[part 1 of 2: package /STELLANTIS/EPT/COMSWCs]
AUTOSAR XML (schema 4-2-2)
package /STELLANTIS/EPT/COMSWCs
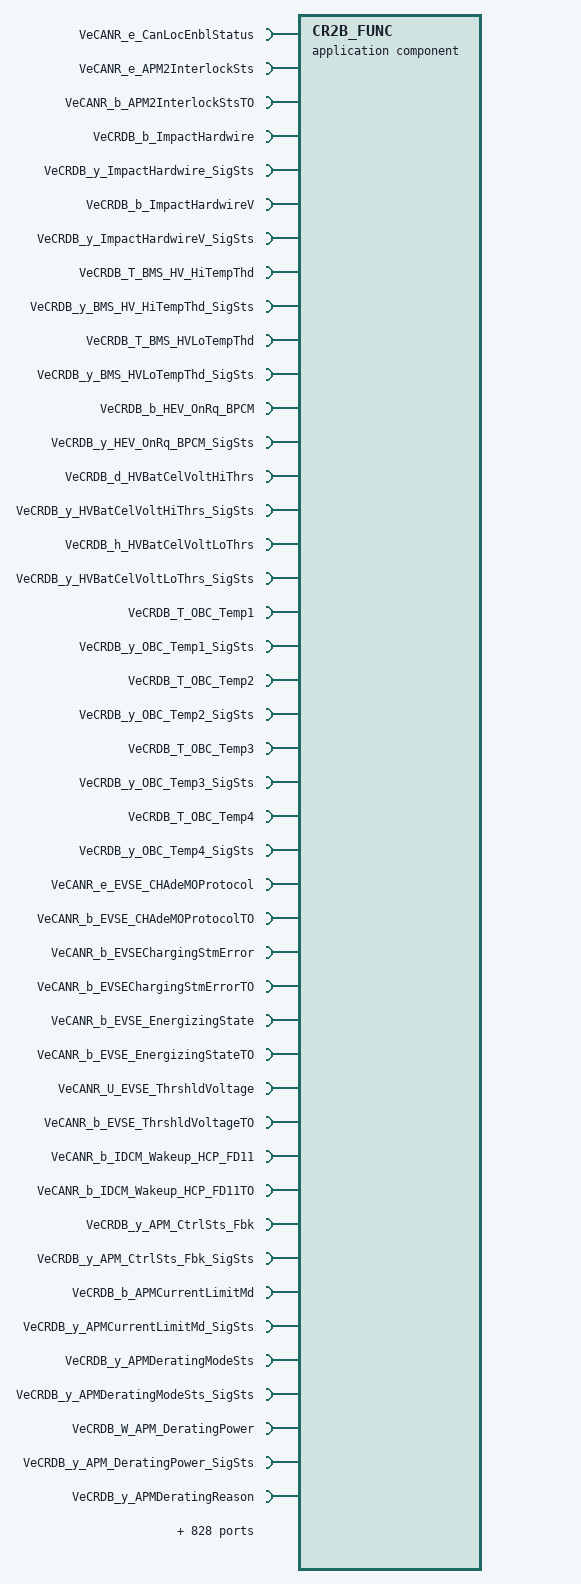
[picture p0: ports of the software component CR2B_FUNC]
  application sw component type CR2B_FUNC
    872 x require port:
      VeCANR_e_CanLocEnblStatus: nonqueued-receiver-com-spec{data-element=VeCANR_e_CanLocEnblStatus, init-value=0}, required-interface=VeCANR_e_CanLocEnblStatus
      VeCANR_e_APM2InterlockSts: nonqueued-receiver-com-spec{data-element=VeCANR_e_APM2InterlockSts, handle-never-received=true, init-value=0}, required-interface=VeCANR_e_APM2InterlockSts
      VeCANR_b_APM2InterlockStsTO: nonqueued-receiver-com-spec{data-element=VeCANR_b_APM2InterlockStsTO, init-value=0}, required-interface=VeCANR_b_APM2InterlockStsTO
      VeCRDB_b_ImpactHardwire: nonqueued-receiver-com-spec{data-element=Value, handle-never-received=true, init-value=0}, required-interface=VeCRDB_b_ImpactHardwire
      VeCRDB_y_ImpactHardwire_SigSts: nonqueued-receiver-com-spec{data-element=Value, init-value=0}, required-interface=VeCRDB_y_ImpactHardwire_SigSts
      VeCRDB_b_ImpactHardwireV: nonqueued-receiver-com-spec{data-element=Value, handle-never-received=true, init-value=0}, required-interface=VeCRDB_b_ImpactHardwireV
      VeCRDB_y_ImpactHardwireV_SigSts: nonqueued-receiver-com-spec{data-element=Value, init-value=0}, required-interface=VeCRDB_y_ImpactHardwireV_SigSts
      VeCRDB_T_BMS_HV_HiTempThd: nonqueued-receiver-com-spec{data-element=Value, handle-never-received=true, init-value=0}, required-interface=VeCRDB_T_BMS_HV_HiTempThd
      VeCRDB_y_BMS_HV_HiTempThd_SigSts: nonqueued-receiver-com-spec{data-element=Value, init-value=0}, required-interface=VeCRDB_y_BMS_HV_HiTempThd_SigSts
      VeCRDB_T_BMS_HVLoTempThd: nonqueued-receiver-com-spec{data-element=Value, handle-never-received=true, init-value=0}, required-interface=VeCRDB_T_BMS_HVLoTempThd
      VeCRDB_y_BMS_HVLoTempThd_SigSts: nonqueued-receiver-com-spec{data-element=Value, init-value=0}, required-interface=VeCRDB_y_BMS_HVLoTempThd_SigSts
      VeCRDB_b_HEV_OnRq_BPCM: nonqueued-receiver-com-spec{data-element=Value, handle-never-received=true, init-value=0}, required-interface=VeCRDB_b_HEV_OnRq_BPCM
      VeCRDB_y_HEV_OnRq_BPCM_SigSts: nonqueued-receiver-com-spec{data-element=Value, init-value=0}, required-interface=VeCRDB_y_HEV_OnRq_BPCM_SigSts
      VeCRDB_d_HVBatCelVoltHiThrs: nonqueued-receiver-com-spec{data-element=Value, handle-never-received=true, init-value=0}, required-interface=VeCRDB_d_HVBatCelVoltHiThrs
      VeCRDB_y_HVBatCelVoltHiThrs_SigSts: nonqueued-receiver-com-spec{data-element=Value, init-value=0}, required-interface=VeCRDB_y_HVBatCelVoltHiThrs_SigSts
      VeCRDB_h_HVBatCelVoltLoThrs: nonqueued-receiver-com-spec{data-element=Value, handle-never-received=true, init-value=0}, required-interface=VeCRDB_h_HVBatCelVoltLoThrs
      VeCRDB_y_HVBatCelVoltLoThrs_SigSts: nonqueued-receiver-com-spec{data-element=Value, init-value=0}, required-interface=VeCRDB_y_HVBatCelVoltLoThrs_SigSts
      VeCRDB_T_OBC_Temp1: nonqueued-receiver-com-spec{data-element=Value, handle-never-received=true, init-value=0}, required-interface=VeCRDB_T_OBC_Temp1
      VeCRDB_y_OBC_Temp1_SigSts: nonqueued-receiver-com-spec{data-element=Value, init-value=0}, required-interface=VeCRDB_y_OBC_Temp1_SigSts
      VeCRDB_T_OBC_Temp2: nonqueued-receiver-com-spec{data-element=Value, handle-never-received=true, init-value=0}, required-interface=VeCRDB_T_OBC_Temp2
      VeCRDB_y_OBC_Temp2_SigSts: nonqueued-receiver-com-spec{data-element=Value, init-value=0}, required-interface=VeCRDB_y_OBC_Temp2_SigSts
      VeCRDB_T_OBC_Temp3: nonqueued-receiver-com-spec{data-element=Value, handle-never-received=true, init-value=0}, required-interface=VeCRDB_T_OBC_Temp3
      VeCRDB_y_OBC_Temp3_SigSts: nonqueued-receiver-com-spec{data-element=Value, init-value=0}, required-interface=VeCRDB_y_OBC_Temp3_SigSts
      VeCRDB_T_OBC_Temp4: nonqueued-receiver-com-spec{data-element=Value, handle-never-received=true, init-value=0}, required-interface=VeCRDB_T_OBC_Temp4
      VeCRDB_y_OBC_Temp4_SigSts: nonqueued-receiver-com-spec{data-element=Value, init-value=0}, required-interface=VeCRDB_y_OBC_Temp4_SigSts
      VeCANR_e_EVSE_CHAdeMOProtocol: nonqueued-receiver-com-spec{data-element=VeCANR_e_EVSE_CHAdeMOProtocol, handle-never-received=true, init-value=0}, required-interface=VeCANR_e_EVSE_CHAdeMOProtocol
      VeCANR_b_EVSE_CHAdeMOProtocolTO: nonqueued-receiver-com-spec{data-element=VeCANR_b_EVSE_CHAdeMOProtocolTO, init-value=0}, required-interface=VeCANR_b_EVSE_CHAdeMOProtocolTO
      VeCANR_b_EVSEChargingStmError: nonqueued-receiver-com-spec{data-element=VeCANR_b_EVSEChargingStmError, handle-never-received=true, init-value=0}, required-interface=VeCANR_b_EVSEChargingStmError
      VeCANR_b_EVSEChargingStmErrorTO: nonqueued-receiver-com-spec{data-element=VeCANR_b_EVSEChargingStmErrorTO, init-value=0}, required-interface=VeCANR_b_EVSEChargingStmErrorTO
      VeCANR_b_EVSE_EnergizingState: nonqueued-receiver-com-spec{data-element=VeCANR_b_EVSE_EnergizingState, handle-never-received=true, init-value=0}, required-interface=VeCANR_b_EVSE_EnergizingState
      VeCANR_b_EVSE_EnergizingStateTO: nonqueued-receiver-com-spec{data-element=VeCANR_b_EVSE_EnergizingStateTO, init-value=0}, required-interface=VeCANR_b_EVSE_EnergizingStateTO
      VeCANR_U_EVSE_ThrshldVoltage: nonqueued-receiver-com-spec{data-element=VeCANR_U_EVSE_ThrshldVoltage, handle-never-received=true, init-value=0}, required-interface=VeCANR_U_EVSE_ThrshldVoltage
      VeCANR_b_EVSE_ThrshldVoltageTO: nonqueued-receiver-com-spec{data-element=VeCANR_b_EVSE_ThrshldVoltageTO, init-value=0}, required-interface=VeCANR_b_EVSE_ThrshldVoltageTO
      VeCANR_b_IDCM_Wakeup_HCP_FD11: nonqueued-receiver-com-spec{data-element=VeCANR_b_IDCM_Wakeup_HCP_FD11, handle-never-received=true, init-value=0}, required-interface=VeCANR_b_IDCM_Wakeup_HCP_FD11
      VeCANR_b_IDCM_Wakeup_HCP_FD11TO: nonqueued-receiver-com-spec{data-element=VeCANR_b_IDCM_Wakeup_HCP_FD11TO, init-value=0}, required-interface=VeCANR_b_IDCM_Wakeup_HCP_FD11TO
      VeCRDB_y_APM_CtrlSts_Fbk: nonqueued-receiver-com-spec{data-element=Value, handle-never-received=true, init-value=0}, required-interface=VeCRDB_y_APM_CtrlSts_Fbk
      VeCRDB_y_APM_CtrlSts_Fbk_SigSts: nonqueued-receiver-com-spec{data-element=Value, init-value=0}, required-interface=VeCRDB_y_APM_CtrlSts_Fbk_SigSts
      VeCRDB_b_APMCurrentLimitMd: nonqueued-receiver-com-spec{data-element=Value, handle-never-received=true, init-value=0}, required-interface=VeCRDB_b_APMCurrentLimitMd
      VeCRDB_y_APMCurrentLimitMd_SigSts: nonqueued-receiver-com-spec{data-element=Value, init-value=0}, required-interface=VeCRDB_y_APMCurrentLimitMd_SigSts
      VeCRDB_y_APMDeratingModeSts: nonqueued-receiver-com-spec{data-element=Value, handle-never-received=true, init-value=0}, required-interface=VeCRDB_y_APMDeratingModeSts
      VeCRDB_y_APMDeratingModeSts_SigSts: nonqueued-receiver-com-spec{data-element=Value, init-value=0}, required-interface=VeCRDB_y_APMDeratingModeSts_SigSts
      VeCRDB_W_APM_DeratingPower: nonqueued-receiver-com-spec{data-element=Value, handle-never-received=true, init-value=0}, required-interface=VeCRDB_W_APM_DeratingPower
      VeCRDB_y_APM_DeratingPower_SigSts: nonqueued-receiver-com-spec{data-element=Value, init-value=0}, required-interface=VeCRDB_y_APM_DeratingPower_SigSts
      VeCRDB_y_APMDeratingReason: nonqueued-receiver-com-spec{data-element=Value, handle-never-received=true, init-value=0}, required-interface=VeCRDB_y_APMDeratingReason
      VeCRDB_y_APMDeratingReason_SigSts: nonqueued-receiver-com-spec{data-element=Value, init-value=0}, required-interface=VeCRDB_y_APMDeratingReason_SigSts
      VeCRDB_W_APM_EstPwrLoss: nonqueued-receiver-com-spec{data-element=Value, handle-never-received=true, init-value=0}, required-interface=VeCRDB_W_APM_EstPwrLoss
      VeCRDB_y_APM_EstPwrLoss_SigSts: nonqueued-receiver-com-spec{data-element=Value, init-value=0}, required-interface=VeCRDB_y_APM_EstPwrLoss_SigSts
      VeCRDB_y_APM_FailureReason: nonqueued-receiver-com-spec{data-element=Value, handle-never-received=true, init-value=0}, required-interface=VeCRDB_y_APM_FailureReason
      VeCRDB_y_APM_FailureReason_SigSts: nonqueued-receiver-com-spec{data-element=Value, init-value=0}, required-interface=VeCRDB_y_APM_FailureReason_SigSts
      VeCRDB_y_APM_FailureType: nonqueued-receiver-com-spec{data-element=Value, handle-never-received=true, init-value=0}, required-interface=VeCRDB_y_APM_FailureType
      VeCRDB_y_APM_FailureType_SigSts: nonqueued-receiver-com-spec{data-element=Value, init-value=0}, required-interface=VeCRDB_y_APM_FailureType_SigSts
      VeCRDB_I_APM_HV_I_Fbk: nonqueued-receiver-com-spec{data-element=Value, handle-never-received=true, init-value=0}, required-interface=VeCRDB_I_APM_HV_I_Fbk
      VeCRDB_y_APM_HV_I_Fbk_SigSts: nonqueued-receiver-com-spec{data-element=Value, init-value=0}, required-interface=VeCRDB_y_APM_HV_I_Fbk_SigSts
      VeCRDB_U_APM_HV_V_Fbk: nonqueued-receiver-com-spec{data-element=Value, handle-never-received=true, init-value=0}, required-interface=VeCRDB_U_APM_HV_V_Fbk
      VeCRDB_y_APM_HV_V_Fbk_SigSts: nonqueued-receiver-com-spec{data-element=Value, init-value=0}, required-interface=VeCRDB_y_APM_HV_V_Fbk_SigSts
      VeCRDB_b_APM_HvOverVStatus: nonqueued-receiver-com-spec{data-element=Value, handle-never-received=true, init-value=0}, required-interface=VeCRDB_b_APM_HvOverVStatus
      VeCRDB_y_APM_HvOverVStatus_SigSts: nonqueued-receiver-com-spec{data-element=Value, init-value=0}, required-interface=VeCRDB_y_APM_HvOverVStatus_SigSts
      VeCRDB_U_APM_HvVsetPFdbk: nonqueued-receiver-com-spec{data-element=Value, handle-never-received=true, init-value=0}, required-interface=VeCRDB_U_APM_HvVsetPFdbk
      VeCRDB_y_APM_HvVsetPFdbk_SigSts: nonqueued-receiver-com-spec{data-element=Value, init-value=0}, required-interface=VeCRDB_y_APM_HvVsetPFdbk_SigSts
      VeCRDB_I_APM_IdcHvSetPFdbk: nonqueued-receiver-com-spec{data-element=Value, handle-never-received=true, init-value=0}, required-interface=VeCRDB_I_APM_IdcHvSetPFdbk
      VeCRDB_y_APM_IdcHvSetPFdbk_SigSts: nonqueued-receiver-com-spec{data-element=Value, init-value=0}, required-interface=VeCRDB_y_APM_IdcHvSetPFdbk_SigSts
      VeCRDB_W_APM_InputPower: nonqueued-receiver-com-spec{data-element=Value, handle-never-received=true, init-value=0}, required-interface=VeCRDB_W_APM_InputPower
      VeCRDB_y_APM_InputPower_SigSts: nonqueued-receiver-com-spec{data-element=Value, init-value=0}, required-interface=VeCRDB_y_APM_InputPower_SigSts
      VeCRDB_I_APM_LV_I_Fbk: nonqueued-receiver-com-spec{data-element=Value, handle-never-received=true, init-value=0}, required-interface=VeCRDB_I_APM_LV_I_Fbk
      VeCRDB_y_APM_LV_I_Fbk_SigSts: nonqueued-receiver-com-spec{data-element=Value, init-value=0}, required-interface=VeCRDB_y_APM_LV_I_Fbk_SigSts
      VeCRDB_U_APM_LV_V_Fbk: nonqueued-receiver-com-spec{data-element=Value, handle-never-received=true, init-value=0}, required-interface=VeCRDB_U_APM_LV_V_Fbk
      VeCRDB_y_APM_LV_V_Fbk_SigSts: nonqueued-receiver-com-spec{data-element=Value, init-value=0}, required-interface=VeCRDB_y_APM_LV_V_Fbk_SigSts
      VeCRDB_W_APM_OutputPower: nonqueued-receiver-com-spec{data-element=Value, handle-never-received=true, init-value=0}, required-interface=VeCRDB_W_APM_OutputPower
      VeCRDB_y_APM_OutputPower_SigSts: nonqueued-receiver-com-spec{data-element=Value, init-value=0}, required-interface=VeCRDB_y_APM_OutputPower_SigSts
      VeCRDB_T_APM_PSFB_Temp1: nonqueued-receiver-com-spec{data-element=Value, handle-never-received=true, init-value=0}, required-interface=VeCRDB_T_APM_PSFB_Temp1
      VeCRDB_y_APM_PSFB_Temp1_SigSts: nonqueued-receiver-com-spec{data-element=Value, init-value=0}, required-interface=VeCRDB_y_APM_PSFB_Temp1_SigSts
      VeCRDB_T_APM_PSFB_Temp2: nonqueued-receiver-com-spec{data-element=Value, handle-never-received=true, init-value=0}, required-interface=VeCRDB_T_APM_PSFB_Temp2
      VeCRDB_y_APM_PSFB_Temp2_SigSts: nonqueued-receiver-com-spec{data-element=Value, init-value=0}, required-interface=VeCRDB_y_APM_PSFB_Temp2_SigSts
      VeCRDB_b_APM_PowerLimitMode: nonqueued-receiver-com-spec{data-element=Value, handle-never-received=true, init-value=0}, required-interface=VeCRDB_b_APM_PowerLimitMode
      VeCRDB_y_APM_PowerLimitMode_SigSts: nonqueued-receiver-com-spec{data-element=Value, init-value=0}, required-interface=VeCRDB_y_APM_PowerLimitMode_SigSts
      VeCRDB_T_APM_TempColdPlate: nonqueued-receiver-com-spec{data-element=Value, handle-never-received=true, init-value=0}, required-interface=VeCRDB_T_APM_TempColdPlate
      VeCRDB_y_APM_TempColdPlate_SigSts: nonqueued-receiver-com-spec{data-element=Value, init-value=0}, required-interface=VeCRDB_y_APM_TempColdPlate_SigSts
      VeCRDB_y_APM_ThermalRunaway: nonqueued-receiver-com-spec{data-element=Value, handle-never-received=true, init-value=0}, required-interface=VeCRDB_y_APM_ThermalRunaway
      VeCRDB_y_APM_ThermalRunaway_SigSts: nonqueued-receiver-com-spec{data-element=Value, init-value=0}, required-interface=VeCRDB_y_APM_ThermalRunaway_SigSts
      VeCRDB_Pct_APMUtlPctOfDCDC: nonqueued-receiver-com-spec{data-element=Value, handle-never-received=true, init-value=0}, required-interface=VeCRDB_Pct_APMUtlPctOfDCDC
      VeCRDB_y_APMUtlPctOfDCDC_SigSts: nonqueued-receiver-com-spec{data-element=Value, init-value=0}, required-interface=VeCRDB_y_APMUtlPctOfDCDC_SigSts
      VeCRDB_b_BPCMCntctrsMTOWrn: nonqueued-receiver-com-spec{data-element=Value, handle-never-received=true, init-value=0}, required-interface=VeCRDB_b_BPCMCntctrsMTOWrn
      VeCRDB_y_BPCMCntctrsMTOWrn_SigSts: nonqueued-receiver-com-spec{data-element=Value, init-value=0}, required-interface=VeCRDB_y_BPCMCntctrsMTOWrn_SigSts
      VeCRDB_b_BPCMCntctrsSTOWrn: nonqueued-receiver-com-spec{data-element=Value, handle-never-received=true, init-value=0}, required-interface=VeCRDB_b_BPCMCntctrsSTOWrn
      VeCRDB_y_BPCMCntctrsSTOWrn_SigSts: nonqueued-receiver-com-spec{data-element=Value, init-value=0}, required-interface=VeCRDB_y_BPCMCntctrsSTOWrn_SigSts
      VeCRDB_dT_BPCM_HVCelMxDchImp: nonqueued-receiver-com-spec{data-element=Value, handle-never-received=true, init-value=0}, required-interface=VeCRDB_dT_BPCM_HVCelMxDchImp
      VeCRDB_y_BPCM_HVCelMxDchImp_SigSts: nonqueued-receiver-com-spec{data-element=Value, init-value=0}, required-interface=VeCRDB_y_BPCM_HVCelMxDchImp_SigSts
      VeCRDB_dT_BPCM_HVClMinDchImp: nonqueued-receiver-com-spec{data-element=Value, handle-never-received=true, init-value=0}, required-interface=VeCRDB_dT_BPCM_HVClMinDchImp
      VeCRDB_y_BPCM_HVClMinDchImp_SigSts: nonqueued-receiver-com-spec{data-element=Value, init-value=0}, required-interface=VeCRDB_y_BPCM_HVClMinDchImp_SigSts
      VeCRDB_I_BPCM_HVChrgCurProf: nonqueued-receiver-com-spec{data-element=Value, handle-never-received=true, init-value=0}, required-interface=VeCRDB_I_BPCM_HVChrgCurProf
      VeCRDB_y_BPCM_HVChrgCurProf_SigSts: nonqueued-receiver-com-spec{data-element=Value, init-value=0}, required-interface=VeCRDB_y_BPCM_HVChrgCurProf_SigSts
      VeCRDB_y_BPCM_HV_BatChrgSts: nonqueued-receiver-com-spec{data-element=Value, handle-never-received=true, init-value=0}, required-interface=VeCRDB_y_BPCM_HV_BatChrgSts
      VeCRDB_y_BPCM_HV_BatChrgSts_SigSts: nonqueued-receiver-com-spec{data-element=Value, init-value=0}, required-interface=VeCRDB_y_BPCM_HV_BatChrgSts_SigSts
      VeCRDB_P_BPCM_HVPwrMaxChgLT: nonqueued-receiver-com-spec{data-element=Value, handle-never-received=true, init-value=0}, required-interface=VeCRDB_P_BPCM_HVPwrMaxChgLT
      VeCRDB_y_BPCM_HVPwrMaxChgLT_SigSts: nonqueued-receiver-com-spec{data-element=Value, init-value=0}, required-interface=VeCRDB_y_BPCM_HVPwrMaxChgLT_SigSts
      VeCRDB_P_BPCM_HVPwrMaxChgMT: nonqueued-receiver-com-spec{data-element=Value, handle-never-received=true, init-value=0}, required-interface=VeCRDB_P_BPCM_HVPwrMaxChgMT
      VeCRDB_y_BPCM_HVPwrMaxChgMT_SigSts: nonqueued-receiver-com-spec{data-element=Value, init-value=0}, required-interface=VeCRDB_y_BPCM_HVPwrMaxChgMT_SigSts
      VeCRDB_P_BPCM_HVPwrMaxChgST: nonqueued-receiver-com-spec{data-element=Value, handle-never-received=true, init-value=0}, required-interface=VeCRDB_P_BPCM_HVPwrMaxChgST
      VeCRDB_y_BPCM_HVPwrMaxChgST_SigSts: nonqueued-receiver-com-spec{data-element=Value, init-value=0}, required-interface=VeCRDB_y_BPCM_HVPwrMaxChgST_SigSts
      VeCRDB_P_BPCM_HVPwrMxDchgLT: nonqueued-receiver-com-spec{data-element=Value, handle-never-received=true, init-value=0}, required-interface=VeCRDB_P_BPCM_HVPwrMxDchgLT
      VeCRDB_y_BPCM_HVPwrMxDchgLT_SigSts: nonqueued-receiver-com-spec{data-element=Value, init-value=0}, required-interface=VeCRDB_y_BPCM_HVPwrMxDchgLT_SigSts
      VeCRDB_P_BPCM_HVPwrMxDchgMT: nonqueued-receiver-com-spec{data-element=Value, handle-never-received=true, init-value=0}, required-interface=VeCRDB_P_BPCM_HVPwrMxDchgMT
      VeCRDB_y_BPCM_HVPwrMxDchgMT_SigSts: nonqueued-receiver-com-spec{data-element=Value, init-value=0}, required-interface=VeCRDB_y_BPCM_HVPwrMxDchgMT_SigSts
      VeCRDB_P_BPCM_HVPwrMxDchgST: nonqueued-receiver-com-spec{data-element=Value, handle-never-received=true, init-value=0}, required-interface=VeCRDB_P_BPCM_HVPwrMxDchgST
      VeCRDB_y_BPCM_HVPwrMxDchgST_SigSts: nonqueued-receiver-com-spec{data-element=Value, init-value=0}, required-interface=VeCRDB_y_BPCM_HVPwrMxDchgST_SigSts
      VeCRDB_y_BPCMInterlockSts: nonqueued-receiver-com-spec{data-element=Value, handle-never-received=true, init-value=0}, required-interface=VeCRDB_y_BPCMInterlockSts
      VeCRDB_y_BPCMInterlockSts_SigSts: nonqueued-receiver-com-spec{data-element=Value, init-value=0}, required-interface=VeCRDB_y_BPCMInterlockSts_SigSts
      VeCRDB_b_BPCM_DCCntctrMTOW: nonqueued-receiver-com-spec{data-element=Value, handle-never-received=true, init-value=0}, required-interface=VeCRDB_b_BPCM_DCCntctrMTOW
      VeCRDB_y_BPCM_DCCntctrMTOW_SigSts: nonqueued-receiver-com-spec{data-element=Value, init-value=0}, required-interface=VeCRDB_y_BPCM_DCCntctrMTOW_SigSts
      VeCRDB_b_BPCM_DCCntctrSTOW: nonqueued-receiver-com-spec{data-element=Value, handle-never-received=true, init-value=0}, required-interface=VeCRDB_b_BPCM_DCCntctrSTOW
      VeCRDB_y_BPCM_DCCntctrSTOW_SigSts: nonqueued-receiver-com-spec{data-element=Value, init-value=0}, required-interface=VeCRDB_y_BPCM_DCCntctrSTOW_SigSts
      VeCRDB_y_BPCM_HV_BalngMd: nonqueued-receiver-com-spec{data-element=Value, handle-never-received=true, init-value=0}, required-interface=VeCRDB_y_BPCM_HV_BalngMd
      VeCRDB_y_BPCM_HV_BalngMd_SigSts: nonqueued-receiver-com-spec{data-element=Value, init-value=0}, required-interface=VeCRDB_y_BPCM_HV_BalngMd_SigSts
      VeCRDB_y_BPCM_HVBIIS: nonqueued-receiver-com-spec{data-element=Value, handle-never-received=true, init-value=0}, required-interface=VeCRDB_y_BPCM_HVBIIS
      VeCRDB_y_BPCM_HVBIIS_SigSts: nonqueued-receiver-com-spec{data-element=Value, init-value=0}, required-interface=VeCRDB_y_BPCM_HVBIIS_SigSts
      VeCRDB_y_BPCM_HVBattGFDSts: nonqueued-receiver-com-spec{data-element=Value, handle-never-received=true, init-value=0}, required-interface=VeCRDB_y_BPCM_HVBattGFDSts
      VeCRDB_y_BPCM_HVBattGFDSts_SigSts: nonqueued-receiver-com-spec{data-element=Value, init-value=0}, required-interface=VeCRDB_y_BPCM_HVBattGFDSts_SigSts
      VeCRDB_qAhr_BPCM_HV_Capacity: nonqueued-receiver-com-spec{data-element=Value, handle-never-received=true, init-value=0}, required-interface=VeCRDB_qAhr_BPCM_HV_Capacity
      VeCRDB_y_BPCM_HV_Capacity_SigSts: nonqueued-receiver-com-spec{data-element=Value, init-value=0}, required-interface=VeCRDB_y_BPCM_HV_Capacity_SigSts
      VeCRDB_y_BPCM_HVChrgBusSts: nonqueued-receiver-com-spec{data-element=Value, handle-never-received=true, init-value=0}, required-interface=VeCRDB_y_BPCM_HVChrgBusSts
      VeCRDB_y_BPCM_HVChrgBusSts_SigSts: nonqueued-receiver-com-spec{data-element=Value, init-value=0}, required-interface=VeCRDB_y_BPCM_HVChrgBusSts_SigSts
      VeCRDB_I_BPCM_HV_Current: nonqueued-receiver-com-spec{data-element=Value, handle-never-received=true, init-value=0}, required-interface=VeCRDB_I_BPCM_HV_Current
      VeCRDB_y_BPCM_HV_Current_SigSts: nonqueued-receiver-com-spec{data-element=Value, init-value=0}, required-interface=VeCRDB_y_BPCM_HV_Current_SigSts
      VeCRDB_I_BPCM_HV_CurrentString2: nonqueued-receiver-com-spec{data-element=Value, handle-never-received=true, init-value=0}, required-interface=VeCRDB_I_BPCM_HV_CurrentString2
      VeCRDB_y_BPCM_HV_CurrentString2_SigSts: nonqueued-receiver-com-spec{data-element=Value, init-value=0}, required-interface=VeCRDB_y_BPCM_HV_CurrentString2_SigSts
      VeCRDB_y_BPCM_HV_DCFC_IsolatnSts: nonqueued-receiver-com-spec{data-element=Value, handle-never-received=true, init-value=0}, required-interface=VeCRDB_y_BPCM_HV_DCFC_IsolatnSts
      VeCRDB_y_BPCM_HV_DCFC_IsolatnSts_SigSts: nonqueued-receiver-com-spec{data-element=Value, init-value=0}, required-interface=VeCRDB_y_BPCM_HV_DCFC_IsolatnSts_SigSts
      VeCRDB_T_BPCM_HV_Inlet_Temp: nonqueued-receiver-com-spec{data-element=Value, handle-never-received=true, init-value=0}, required-interface=VeCRDB_T_BPCM_HV_Inlet_Temp
      VeCRDB_y_BPCM_HV_Inlet_Temp_SigSts: nonqueued-receiver-com-spec{data-element=Value, init-value=0}, required-interface=VeCRDB_y_BPCM_HV_Inlet_Temp_SigSts
      VeCRDB_U_BPCM_HV_IntVolt: nonqueued-receiver-com-spec{data-element=Value, handle-never-received=true, init-value=0}, required-interface=VeCRDB_U_BPCM_HV_IntVolt
      VeCRDB_y_BPCM_HV_IntVolt_SigSts: nonqueued-receiver-com-spec{data-element=Value, init-value=0}, required-interface=VeCRDB_y_BPCM_HV_IntVolt_SigSts
      VeCRDB_U_BPCM_HVIntrnlVltStrng1: nonqueued-receiver-com-spec{data-element=Value, handle-never-received=true, init-value=0}, required-interface=VeCRDB_U_BPCM_HVIntrnlVltStrng1
      VeCRDB_y_BPCM_HVIntrnlVltStrng1_SigSts: nonqueued-receiver-com-spec{data-element=Value, init-value=0}, required-interface=VeCRDB_y_BPCM_HVIntrnlVltStrng1_SigSts
      VeCRDB_U_BPCM_HVIntrnlVltStrng2: nonqueued-receiver-com-spec{data-element=Value, handle-never-received=true, init-value=0}, required-interface=VeCRDB_U_BPCM_HVIntrnlVltStrng2
      VeCRDB_y_BPCM_HVIntrnlVltStrng2_SigSts: nonqueued-receiver-com-spec{data-element=Value, init-value=0}, required-interface=VeCRDB_y_BPCM_HVIntrnlVltStrng2_SigSts
      VeCRDB_T_BPCM_HV_Outl_Temp: nonqueued-receiver-com-spec{data-element=Value, handle-never-received=true, init-value=0}, required-interface=VeCRDB_T_BPCM_HV_Outl_Temp
      VeCRDB_y_BPCM_HV_Outl_Temp_SigSts: nonqueued-receiver-com-spec{data-element=Value, init-value=0}, required-interface=VeCRDB_y_BPCM_HV_Outl_Temp_SigSts
      VeCRDB_Pct_BPCM_HV_SOC: nonqueued-receiver-com-spec{data-element=Value, handle-never-received=true, init-value=0}, required-interface=VeCRDB_Pct_BPCM_HV_SOC
      VeCRDB_y_BPCM_HV_SOC_SigSts: nonqueued-receiver-com-spec{data-element=Value, init-value=0}, required-interface=VeCRDB_y_BPCM_HV_SOC_SigSts
      VeCRDB_y_BPCM_HV_SOH: nonqueued-receiver-com-spec{data-element=Value, handle-never-received=true, init-value=0}, required-interface=VeCRDB_y_BPCM_HV_SOH
      VeCRDB_y_BPCM_HV_SOH_SigSts: nonqueued-receiver-com-spec{data-element=Value, init-value=0}, required-interface=VeCRDB_y_BPCM_HV_SOH_SigSts
      VeCRDB_y_BPCM_HV_SOH_Low: nonqueued-receiver-com-spec{data-element=Value, handle-never-received=true, init-value=0}, required-interface=VeCRDB_y_BPCM_HV_SOH_Low
      VeCRDB_y_BPCM_HV_SOH_Low_SigSts: nonqueued-receiver-com-spec{data-element=Value, init-value=0}, required-interface=VeCRDB_y_BPCM_HV_SOH_Low_SigSts
      VeCRDB_T_BPCM_HV_Temp_Avg: nonqueued-receiver-com-spec{data-element=Value, handle-never-received=true, init-value=0}, required-interface=VeCRDB_T_BPCM_HV_Temp_Avg
      VeCRDB_y_BPCM_HV_Temp_Avg_SigSts: nonqueued-receiver-com-spec{data-element=Value, init-value=0}, required-interface=VeCRDB_y_BPCM_HV_Temp_Avg_SigSts
      VeCRDB_T_BPCM_HV_Temp_Max: nonqueued-receiver-com-spec{data-element=Value, handle-never-received=true, init-value=0}, required-interface=VeCRDB_T_BPCM_HV_Temp_Max
      VeCRDB_y_BPCM_HV_Temp_Max_SigSts: nonqueued-receiver-com-spec{data-element=Value, init-value=0}, required-interface=VeCRDB_y_BPCM_HV_Temp_Max_SigSts
      VeCRDB_T_BPCM_HV_Temp_Min: nonqueued-receiver-com-spec{data-element=Value, handle-never-received=true, init-value=0}, required-interface=VeCRDB_T_BPCM_HV_Temp_Min
      VeCRDB_y_BPCM_HV_Temp_Min_SigSts: nonqueued-receiver-com-spec{data-element=Value, init-value=0}, required-interface=VeCRDB_y_BPCM_HV_Temp_Min_SigSts
      VeCRDB_y_BPCM_HV_ThermRnway: nonqueued-receiver-com-spec{data-element=Value, handle-never-received=true, init-value=0}, required-interface=VeCRDB_y_BPCM_HV_ThermRnway
      VeCRDB_y_BPCM_HV_ThermRnway_SigSts: nonqueued-receiver-com-spec{data-element=Value, init-value=0}, required-interface=VeCRDB_y_BPCM_HV_ThermRnway_SigSts
      VeCRDB_y_BPCM_HV_TracBusSts: nonqueued-receiver-com-spec{data-element=Value, handle-never-received=true, init-value=0}, required-interface=VeCRDB_y_BPCM_HV_TracBusSts
      VeCRDB_y_BPCM_HV_TracBusSts_SigSts: nonqueued-receiver-com-spec{data-element=Value, init-value=0}, required-interface=VeCRDB_y_BPCM_HV_TracBusSts_SigSts
      VeCRDB_y_BPCM_HVTracMainCntacCfg: variation-point={short-label=vpVeCRDB_y_BPCM_HVTracMainCntacCfg, sw-syscond=1}, nonqueued-receiver-com-spec{data-element=Value, handle-never-received=true, init-value=0}, required-interface=VeCRDB_y_BPCM_HVTracMainCntacCfg
      VeCRDB_y_BPCM_HVTracMainCntacCfg_SigSts: variation-point={short-label=vpVeCRDB_y_BPCM_HVTracMainCntacCfg_SigSts, sw-syscond=1}, nonqueued-receiver-com-spec{data-element=Value, init-value=0}, required-interface=VeCRDB_y_BPCM_HVTracMainCntacCfg_SigSts
      VeCRDB_y_BPCM_HVTracMCS: nonqueued-receiver-com-spec{data-element=Value, handle-never-received=true, init-value=0}, required-interface=VeCRDB_y_BPCM_HVTracMCS
      VeCRDB_y_BPCM_HVTracMCS_SigSts: nonqueued-receiver-com-spec{data-element=Value, init-value=0}, required-interface=VeCRDB_y_BPCM_HVTracMCS_SigSts
      VeCRDB_U_BPCM_HVTracBusVolt: nonqueued-receiver-com-spec{data-element=Value, handle-never-received=true, init-value=0}, required-interface=VeCRDB_U_BPCM_HVTracBusVolt
      VeCRDB_y_BPCM_HVTracBusVolt_SigSts: nonqueued-receiver-com-spec{data-element=Value, init-value=0}, required-interface=VeCRDB_y_BPCM_HVTracBusVolt_SigSts
      VeCRDB_b_BPCM_PwrLimpHm: nonqueued-receiver-com-spec{data-element=Value, handle-never-received=true, init-value=0}, required-interface=VeCRDB_b_BPCM_PwrLimpHm
      VeCRDB_y_BPCM_PwrLimpHm_SigSts: nonqueued-receiver-com-spec{data-element=Value, init-value=0}, required-interface=VeCRDB_y_BPCM_PwrLimpHm_SigSts
      VeCRDB_b_BPCM_ReqforAuxLoadoff: variation-point={short-label=vpVeCRDB_b_BPCM_ReqforAuxLoadoff, sw-syscond=1}, nonqueued-receiver-com-spec{data-element=Value, handle-never-received=true, init-value=0}, required-interface=VeCRDB_b_BPCM_ReqforAuxLoadoff
      VeCRDB_y_BPCM_ReqforAuxLoadoff_SigSts: variation-point={short-label=vpVeCRDB_y_BPCM_ReqforAuxLoadoff_SigSts, sw-syscond=1}, nonqueued-receiver-com-spec{data-element=Value, init-value=0}, required-interface=VeCRDB_y_BPCM_ReqforAuxLoadoff_SigSts
      VeCRDB_U_BPCM_Series_Voltage: variation-point={short-label=vpVeCRDB_U_BPCM_Series_Voltage, sw-syscond=1}, nonqueued-receiver-com-spec{data-element=Value, handle-never-received=true, init-value=0}, required-interface=VeCRDB_U_BPCM_Series_Voltage
      VeCRDB_y_BPCM_Series_Voltage_SigSts: variation-point={short-label=vpVeCRDB_y_BPCM_Series_Voltage_SigSts, sw-syscond=1}, nonqueued-receiver-com-spec{data-element=Value, init-value=0}, required-interface=VeCRDB_y_BPCM_Series_Voltage_SigSts
      VeCRDB_y_DC_Charge_Type_Status: variation-point={short-label=vpVeCRDB_y_DC_Charge_Type_Status, sw-syscond=1}, nonqueued-receiver-com-spec{data-element=Value, handle-never-received=true, init-value=0}, required-interface=VeCRDB_y_DC_Charge_Type_Status
      VeCRDB_y_DC_Charge_Type_Status_SigSts: variation-point={short-label=vpVeCRDB_y_DC_Charge_Type_Status_SigSts, sw-syscond=1}, nonqueued-receiver-com-spec{data-element=Value, init-value=0}, required-interface=VeCRDB_y_DC_Charge_Type_Status_SigSts
      VeCRDB_T_HVBP_BDU_Busbar_Temp: nonqueued-receiver-com-spec{data-element=Value, handle-never-received=true, init-value=0}, required-interface=VeCRDB_T_HVBP_BDU_Busbar_Temp
      VeCRDB_y_HVBP_BDU_Busbar_Temp_SigSts: nonqueued-receiver-com-spec{data-element=Value, init-value=0}, required-interface=VeCRDB_y_HVBP_BDU_Busbar_Temp_SigSts
      VeCRDB_T_HVBP_Busbar_Temp: nonqueued-receiver-com-spec{data-element=Value, handle-never-received=true, init-value=0}, required-interface=VeCRDB_T_HVBP_Busbar_Temp
      VeCRDB_y_HVBP_Busbar_Temp_SigSts: nonqueued-receiver-com-spec{data-element=Value, init-value=0}, required-interface=VeCRDB_y_HVBP_Busbar_Temp_SigSts
      VeCRDB_thr_HVBatCntctOpnTime: nonqueued-receiver-com-spec{data-element=Value, handle-never-received=true, init-value=0}, required-interface=VeCRDB_thr_HVBatCntctOpnTime
      VeCRDB_y_HVBatCntctOpnTime_SigSts: nonqueued-receiver-com-spec{data-element=Value, init-value=0}, required-interface=VeCRDB_y_HVBatCntctOpnTime_SigSts
      VeCRDB_b_HVBatCntctWeldChk: nonqueued-receiver-com-spec{data-element=Value, handle-never-received=true, init-value=0}, required-interface=VeCRDB_b_HVBatCntctWeldChk
      VeCRDB_y_HVBatCntctWeldChk_SigSts: nonqueued-receiver-com-spec{data-element=Value, init-value=0}, required-interface=VeCRDB_y_HVBatCntctWeldChk_SigSts
      VeCRDB_tdy_HVBatLastSlept: nonqueued-receiver-com-spec{data-element=Value, handle-never-received=true, init-value=0}, required-interface=VeCRDB_tdy_HVBatLastSlept
      VeCRDB_y_HVBatLastSlept_SigSts: nonqueued-receiver-com-spec{data-element=Value, init-value=0}, required-interface=VeCRDB_y_HVBatLastSlept_SigSts
      VeCRDB_b_HVBatReady: nonqueued-receiver-com-spec{data-element=Value, handle-never-received=true, init-value=0}, required-interface=VeCRDB_b_HVBatReady
      VeCRDB_y_HVBatReady_SigSts: nonqueued-receiver-com-spec{data-element=Value, init-value=0}, required-interface=VeCRDB_y_HVBatReady_SigSts
      VeCRDB_U_BPCM_Cell_VoltAvg: nonqueued-receiver-com-spec{data-element=Value, handle-never-received=true, init-value=0}, required-interface=VeCRDB_U_BPCM_Cell_VoltAvg
      VeCRDB_y_BPCM_Cell_VoltAvg_SigSts: nonqueued-receiver-com-spec{data-element=Value, init-value=0}, required-interface=VeCRDB_y_BPCM_Cell_VoltAvg_SigSts
      VeCRDB_U_BPCM_Cell_Volt_Max: nonqueued-receiver-com-spec{data-element=Value, handle-never-received=true, init-value=0}, required-interface=VeCRDB_U_BPCM_Cell_Volt_Max
      VeCRDB_y_BPCM_Cell_Volt_Max_SigSts: nonqueued-receiver-com-spec{data-element=Value, init-value=0}, required-interface=VeCRDB_y_BPCM_Cell_Volt_Max_SigSts
      VeCRDB_U_BPCM_Cell_Volt_Min: nonqueued-receiver-com-spec{data-element=Value, handle-never-received=true, init-value=0}, required-interface=VeCRDB_U_BPCM_Cell_Volt_Min
      VeCRDB_y_BPCM_Cell_Volt_Min_SigSts: nonqueued-receiver-com-spec{data-element=Value, init-value=0}, required-interface=VeCRDB_y_BPCM_Cell_Volt_Min_SigSts
      VeCRDB_d_BPCM_HVNrCelMaxTmp: nonqueued-receiver-com-spec{data-element=Value, handle-never-received=true, init-value=0}, required-interface=VeCRDB_d_BPCM_HVNrCelMaxTmp
      VeCRDB_y_BPCM_HVNrCelMaxTmp_SigSts: nonqueued-receiver-com-spec{data-element=Value, init-value=0}, required-interface=VeCRDB_y_BPCM_HVNrCelMaxTmp_SigSts
      VeCRDB_d_BPCM_HVNrCelMaxVlt: nonqueued-receiver-com-spec{data-element=Value, handle-never-received=true, init-value=0}, required-interface=VeCRDB_d_BPCM_HVNrCelMaxVlt
      VeCRDB_y_BPCM_HVNrCelMaxVlt_SigSts: nonqueued-receiver-com-spec{data-element=Value, init-value=0}, required-interface=VeCRDB_y_BPCM_HVNrCelMaxVlt_SigSts
      VeCRDB_d_BPCM_HVNrCelMinTmp: nonqueued-receiver-com-spec{data-element=Value, handle-never-received=true, init-value=0}, required-interface=VeCRDB_d_BPCM_HVNrCelMinTmp
      VeCRDB_y_BPCM_HVNrCelMinTmp_SigSts: nonqueued-receiver-com-spec{data-element=Value, init-value=0}, required-interface=VeCRDB_y_BPCM_HVNrCelMinTmp_SigSts
      VeCRDB_d_BPCM_HVNrCelMinVlt: nonqueued-receiver-com-spec{data-element=Value, handle-never-received=true, init-value=0}, required-interface=VeCRDB_d_BPCM_HVNrCelMinVlt
      VeCRDB_y_BPCM_HVNrCelMinVlt_SigSts: nonqueued-receiver-com-spec{data-element=Value, init-value=0}, required-interface=VeCRDB_y_BPCM_HVNrCelMinVlt_SigSts
      VeCRDB_U_BPCMMaxCelVoltAlwd: nonqueued-receiver-com-spec{data-element=Value, handle-never-received=true, init-value=0}, required-interface=VeCRDB_U_BPCMMaxCelVoltAlwd
      VeCRDB_y_BPCMMaxCelVoltAlwd_SigSts: nonqueued-receiver-com-spec{data-element=Value, init-value=0}, required-interface=VeCRDB_y_BPCMMaxCelVoltAlwd_SigSts
      VeCRDB_U_BPCMMaxPkVoltAllwd: nonqueued-receiver-com-spec{data-element=Value, handle-never-received=true, init-value=0}, required-interface=VeCRDB_U_BPCMMaxPkVoltAllwd
      VeCRDB_y_BPCMMaxPkVoltAllwd_SigSts: nonqueued-receiver-com-spec{data-element=Value, init-value=0}, required-interface=VeCRDB_y_BPCMMaxPkVoltAllwd_SigSts
      VeCRDB_U_BPCMMinCelVoltAlwd: nonqueued-receiver-com-spec{data-element=Value, handle-never-received=true, init-value=0}, required-interface=VeCRDB_U_BPCMMinCelVoltAlwd
      VeCRDB_y_BPCMMinCelVoltAlwd_SigSts: nonqueued-receiver-com-spec{data-element=Value, init-value=0}, required-interface=VeCRDB_y_BPCMMinCelVoltAlwd_SigSts
      VeCRDB_U_BPCMMinPkVoltAllwd: nonqueued-receiver-com-spec{data-element=Value, handle-never-received=true, init-value=0}, required-interface=VeCRDB_U_BPCMMinPkVoltAllwd
      VeCRDB_y_BPCMMinPkVoltAllwd_SigSts: nonqueued-receiver-com-spec{data-element=Value, init-value=0}, required-interface=VeCRDB_y_BPCMMinPkVoltAllwd_SigSts
      VeCRDB_U_BPCM_OCVAvgCelVolt: nonqueued-receiver-com-spec{data-element=Value, handle-never-received=true, init-value=0}, required-interface=VeCRDB_U_BPCM_OCVAvgCelVolt
      VeCRDB_y_BPCM_OCVAvgCelVolt_SigSts: nonqueued-receiver-com-spec{data-element=Value, init-value=0}, required-interface=VeCRDB_y_BPCM_OCVAvgCelVolt_SigSts
      VeCRDB_U_BPCM_OCVMaxCelVolt: nonqueued-receiver-com-spec{data-element=Value, handle-never-received=true, init-value=0}, required-interface=VeCRDB_U_BPCM_OCVMaxCelVolt
      VeCRDB_y_BPCM_OCVMaxCelVolt_SigSts: nonqueued-receiver-com-spec{data-element=Value, init-value=0}, required-interface=VeCRDB_y_BPCM_OCVMaxCelVolt_SigSts
      VeCRDB_U_BPCM_OCVMinCelVolt: nonqueued-receiver-com-spec{data-element=Value, handle-never-received=true, init-value=0}, required-interface=VeCRDB_U_BPCM_OCVMinCelVolt
      VeCRDB_y_BPCM_OCVMinCelVolt_SigSts: nonqueued-receiver-com-spec{data-element=Value, init-value=0}, required-interface=VeCRDB_y_BPCM_OCVMinCelVolt_SigSts
      VeCRDB_b_AC_LnHi: nonqueued-receiver-com-spec{data-element=Value, handle-never-received=true, init-value=0}, required-interface=VeCRDB_b_AC_LnHi
      VeCRDB_y_AC_LnHi_SigSts: nonqueued-receiver-com-spec{data-element=Value, init-value=0}, required-interface=VeCRDB_y_AC_LnHi_SigSts
      VeCRDB_b_AC_LnLow: nonqueued-receiver-com-spec{data-element=Value, handle-never-received=true, init-value=0}, required-interface=VeCRDB_b_AC_LnLow
      VeCRDB_y_AC_LnLow_SigSts: nonqueued-receiver-com-spec{data-element=Value, init-value=0}, required-interface=VeCRDB_y_AC_LnLow_SigSts
      VeCRDB_b_AC_Present: nonqueued-receiver-com-spec{data-element=Value, handle-never-received=true, init-value=0}, required-interface=VeCRDB_b_AC_Present
      VeCRDB_y_AC_Present_SigSts: nonqueued-receiver-com-spec{data-element=Value, init-value=0}, required-interface=VeCRDB_y_AC_Present_SigSts
      VeCRDB_I_AC_Side_Curr1: nonqueued-receiver-com-spec{data-element=Value, handle-never-received=true, init-value=0}, required-interface=VeCRDB_I_AC_Side_Curr1
      VeCRDB_y_AC_Side_Curr1_SigSts: nonqueued-receiver-com-spec{data-element=Value, init-value=0}, required-interface=VeCRDB_y_AC_Side_Curr1_SigSts
      VeCRDB_I_AC_Side_Curr2: nonqueued-receiver-com-spec{data-element=Value, handle-never-received=true, init-value=0}, required-interface=VeCRDB_I_AC_Side_Curr2
      VeCRDB_y_AC_Side_Curr2_SigSts: nonqueued-receiver-com-spec{data-element=Value, init-value=0}, required-interface=VeCRDB_y_AC_Side_Curr2_SigSts
      VeCRDB_I_AC_Side_Curr3: nonqueued-receiver-com-spec{data-element=Value, handle-never-received=true, init-value=0}, required-interface=VeCRDB_I_AC_Side_Curr3
      VeCRDB_y_AC_Side_Curr3_SigSts: nonqueued-receiver-com-spec{data-element=Value, init-value=0}, required-interface=VeCRDB_y_AC_Side_Curr3_SigSts
      VeCRDB_U_AC_Side_Volt1: nonqueued-receiver-com-spec{data-element=Value, handle-never-received=true, init-value=0}, required-interface=VeCRDB_U_AC_Side_Volt1
      VeCRDB_y_AC_Side_Volt1_SigSts: nonqueued-receiver-com-spec{data-element=Value, init-value=0}, required-interface=VeCRDB_y_AC_Side_Volt1_SigSts
      VeCRDB_U_AC_Side_Volt2: nonqueued-receiver-com-spec{data-element=Value, handle-never-received=true, init-value=0}, required-interface=VeCRDB_U_AC_Side_Volt2
      VeCRDB_y_AC_Side_Volt2_SigSts: nonqueued-receiver-com-spec{data-element=Value, init-value=0}, required-interface=VeCRDB_y_AC_Side_Volt2_SigSts
      VeCRDB_U_AC_Side_Volt3: nonqueued-receiver-com-spec{data-element=Value, handle-never-received=true, init-value=0}, required-interface=VeCRDB_U_AC_Side_Volt3
      VeCRDB_y_AC_Side_Volt3_SigSts: nonqueued-receiver-com-spec{data-element=Value, init-value=0}, required-interface=VeCRDB_y_AC_Side_Volt3_SigSts
      VeCRDB_I_BatterySideCurrent: nonqueued-receiver-com-spec{data-element=Value, handle-never-received=true, init-value=0}, required-interface=VeCRDB_I_BatterySideCurrent
      VeCRDB_y_BatterySideCurrent_SigSts: nonqueued-receiver-com-spec{data-element=Value, init-value=0}, required-interface=VeCRDB_y_BatterySideCurrent_SigSts
      VeCRDB_U_BatterySideVoltage: nonqueued-receiver-com-spec{data-element=Value, handle-never-received=true, init-value=0}, required-interface=VeCRDB_U_BatterySideVoltage
      VeCRDB_y_BatterySideVoltage_SigSts: nonqueued-receiver-com-spec{data-element=Value, init-value=0}, required-interface=VeCRDB_y_BatterySideVoltage_SigSts
      VeCRDB_I_ChargeCurrent: nonqueued-receiver-com-spec{data-element=Value, handle-never-received=true, init-value=0}, required-interface=VeCRDB_I_ChargeCurrent
      VeCRDB_y_ChargeCurrent_SigSts: nonqueued-receiver-com-spec{data-element=Value, init-value=0}, required-interface=VeCRDB_y_ChargeCurrent_SigSts
      VeCRDB_I_ChrgCurrAvail: nonqueued-receiver-com-spec{data-element=Value, handle-never-received=true, init-value=0}, required-interface=VeCRDB_I_ChrgCurrAvail
      VeCRDB_y_ChrgCurrAvail_SigSts: nonqueued-receiver-com-spec{data-element=Value, init-value=0}, required-interface=VeCRDB_y_ChrgCurrAvail_SigSts
      VeCRDB_y_ControlPilotSts: nonqueued-receiver-com-spec{data-element=Value, handle-never-received=true, init-value=0}, required-interface=VeCRDB_y_ControlPilotSts
      VeCRDB_y_ControlPilotSts_SigSts: nonqueued-receiver-com-spec{data-element=Value, init-value=0}, required-interface=VeCRDB_y_ControlPilotSts_SigSts
      VeCRDB_y_EVCCFailrReason: nonqueued-receiver-com-spec{data-element=Value, handle-never-received=true, init-value=0}, required-interface=VeCRDB_y_EVCCFailrReason
      VeCRDB_y_EVCCFailrReason_SigSts: nonqueued-receiver-com-spec{data-element=Value, init-value=0}, required-interface=VeCRDB_y_EVCCFailrReason_SigSts
      VeCRDB_I_InputCurrentAvail: nonqueued-receiver-com-spec{data-element=Value, handle-never-received=true, init-value=0}, required-interface=VeCRDB_I_InputCurrentAvail
      VeCRDB_y_InputCurrentAvail_SigSts: nonqueued-receiver-com-spec{data-element=Value, init-value=0}, required-interface=VeCRDB_y_InputCurrentAvail_SigSts
      VeCRDB_b_J1772_S2_Sts: nonqueued-receiver-com-spec{data-element=Value, handle-never-received=true, init-value=0}, required-interface=VeCRDB_b_J1772_S2_Sts
      VeCRDB_y_J1772_S2_Sts_SigSts: nonqueued-receiver-com-spec{data-element=Value, init-value=0}, required-interface=VeCRDB_y_J1772_S2_Sts_SigSts
      VeCRDB_y_J1772_State: nonqueued-receiver-com-spec{data-element=Value, handle-never-received=true, init-value=0}, required-interface=VeCRDB_y_J1772_State
      VeCRDB_y_J1772_State_SigSts: nonqueued-receiver-com-spec{data-element=Value, init-value=0}, required-interface=VeCRDB_y_J1772_State_SigSts
      VeCRDB_y_OBCInterlockSts: nonqueued-receiver-com-spec{data-element=Value, handle-never-received=true, init-value=0}, required-interface=VeCRDB_y_OBCInterlockSts
      VeCRDB_y_OBCInterlockSts_SigSts: nonqueued-receiver-com-spec{data-element=Value, init-value=0}, required-interface=VeCRDB_y_OBCInterlockSts_SigSts
      VeCRDB_y_OBCM_SdpSts: nonqueued-receiver-com-spec{data-element=Value, handle-never-received=true, init-value=0}, required-interface=VeCRDB_y_OBCM_SdpSts
      VeCRDB_y_OBCM_SdpSts_SigSts: nonqueued-receiver-com-spec{data-element=Value, init-value=0}, required-interface=VeCRDB_y_OBCM_SdpSts_SigSts
      VeCRDB_y_OBCM_SlacSts: nonqueued-receiver-com-spec{data-element=Value, handle-never-received=true, init-value=0}, required-interface=VeCRDB_y_OBCM_SlacSts
      VeCRDB_y_OBCM_SlacSts_SigSts: nonqueued-receiver-com-spec{data-element=Value, init-value=0}, required-interface=VeCRDB_y_OBCM_SlacSts_SigSts
      VeCRDB_y_ProximitySts: nonqueued-receiver-com-spec{data-element=Value, handle-never-received=true, init-value=0}, required-interface=VeCRDB_y_ProximitySts
      VeCRDB_y_ProximitySts_SigSts: nonqueued-receiver-com-spec{data-element=Value, init-value=0}, required-interface=VeCRDB_y_ProximitySts_SigSts
      VeCRDB_y_SuprtdProtocolName: nonqueued-receiver-com-spec{data-element=Value, handle-never-received=true, init-value=0}, required-interface=VeCRDB_y_SuprtdProtocolName
      VeCRDB_y_SuprtdProtocolName_SigSts: nonqueued-receiver-com-spec{data-element=Value, init-value=0}, required-interface=VeCRDB_y_SuprtdProtocolName_SigSts
      VeCRDB_y_Supported_SchemaID: nonqueued-receiver-com-spec{data-element=Value, handle-never-received=true, init-value=0}, required-interface=VeCRDB_y_Supported_SchemaID
      VeCRDB_y_Supported_SchemaID_SigSts: nonqueued-receiver-com-spec{data-element=Value, init-value=0}, required-interface=VeCRDB_y_Supported_SchemaID_SigSts
      VeCRDB_y_SuprtdVerNrMajor: nonqueued-receiver-com-spec{data-element=Value, handle-never-received=true, init-value=0}, required-interface=VeCRDB_y_SuprtdVerNrMajor
      VeCRDB_y_SuprtdVerNrMajor_SigSts: nonqueued-receiver-com-spec{data-element=Value, init-value=0}, required-interface=VeCRDB_y_SuprtdVerNrMajor_SigSts
      VeCRDB_y_SuprtdVerNrMinor: nonqueued-receiver-com-spec{data-element=Value, handle-never-received=true, init-value=0}, required-interface=VeCRDB_y_SuprtdVerNrMinor
      VeCRDB_y_SuprtdVerNrMinor_SigSts: nonqueued-receiver-com-spec{data-element=Value, init-value=0}, required-interface=VeCRDB_y_SuprtdVerNrMinor_SigSts
      VeCRDB_y_ChrgFailSts: nonqueued-receiver-com-spec{data-element=Value, handle-never-received=true, init-value=0}, required-interface=VeCRDB_y_ChrgFailSts
      VeCRDB_y_ChrgFailSts_SigSts: nonqueued-receiver-com-spec{data-element=Value, init-value=0}, required-interface=VeCRDB_y_ChrgFailSts_SigSts
      VeCRDB_U_OBC_Prox: nonqueued-receiver-com-spec{data-element=Value, handle-never-received=true, init-value=0}, required-interface=VeCRDB_U_OBC_Prox
      VeCRDB_y_OBC_Prox_SigSts: nonqueued-receiver-com-spec{data-element=Value, init-value=0}, required-interface=VeCRDB_y_OBC_Prox_SigSts
      VeCRDB_y_OnboardChargerMode: nonqueued-receiver-com-spec{data-element=Value, handle-never-received=true, init-value=0}, required-interface=VeCRDB_y_OnboardChargerMode
      VeCRDB_y_OnboardChargerMode_SigSts: nonqueued-receiver-com-spec{data-element=Value, init-value=0}, required-interface=VeCRDB_y_OnboardChargerMode_SigSts
      VeCRDB_y_OnboardChrgrReady: nonqueued-receiver-com-spec{data-element=Value, handle-never-received=true, init-value=0}, required-interface=VeCRDB_y_OnboardChrgrReady
      VeCRDB_y_OnboardChrgrReady_SigSts: nonqueued-receiver-com-spec{data-element=Value, init-value=0}, required-interface=VeCRDB_y_OnboardChrgrReady_SigSts
      VeCRDB_b_EVSE_OfdACSingPhas: nonqueued-receiver-com-spec{data-element=Value, handle-never-received=true, init-value=0}, required-interface=VeCRDB_b_EVSE_OfdACSingPhas
      VeCRDB_y_EVSE_OfdACSingPhas_SigSts: nonqueued-receiver-com-spec{data-element=Value, init-value=0}, required-interface=VeCRDB_y_EVSE_OfdACSingPhas_SigSts
      VeCRDB_b_EVSEOfdACThreePhas: nonqueued-receiver-com-spec{data-element=Value, handle-never-received=true, init-value=0}, required-interface=VeCRDB_b_EVSEOfdACThreePhas
      VeCRDB_y_EVSEOfdACThreePhas_SigSts: nonqueued-receiver-com-spec{data-element=Value, init-value=0}, required-interface=VeCRDB_y_EVSEOfdACThreePhas_SigSts
      VeSR1B_b_EVSE_Ofd_DC_Extended: nonqueued-receiver-com-spec{data-element=Value, handle-never-received=true, init-value=0}, required-interface=VeSR1B_b_EVSE_Ofd_DC_Extended
      VeSR1B_y_EVSE_Ofd_DC_Extended_SigSts: nonqueued-receiver-com-spec{data-element=Value, init-value=0}, required-interface=VeSR1B_y_EVSE_Ofd_DC_Extended_SigSts
      VeSR1B_b_EVSEServ1ChargnFD11: nonqueued-receiver-com-spec{data-element=Value, handle-never-received=true, init-value=0}, required-interface=VeSR1B_b_EVSEServ1ChargnFD11
      VeSR1B_y_EVSEServ1ChargnFD11_SigSts: nonqueued-receiver-com-spec{data-element=Value, init-value=0}, required-interface=VeSR1B_y_EVSEServ1ChargnFD11_SigSts
      VeSR1B_b_EVSE_Service1_FreeFD11: nonqueued-receiver-com-spec{data-element=Value, handle-never-received=true, init-value=0}, required-interface=VeSR1B_b_EVSE_Service1_FreeFD11
      VeSR1B_y_EVSE_Service1_FreeFD11_SigSts: nonqueued-receiver-com-spec{data-element=Value, init-value=0}, required-interface=VeSR1B_y_EVSE_Service1_FreeFD11_SigSts
      VeSR1B_cmp_ISO15118EVSETiStFD11: nonqueued-receiver-com-spec{data-element=Value, handle-never-received=true, init-value=0}, required-interface=VeSR1B_cmp_ISO15118EVSETiStFD11
      VeSR1B_y_ISO15118EVSETiStFD11_SigSts: nonqueued-receiver-com-spec{data-element=Value, init-value=0}, required-interface=VeSR1B_y_ISO15118EVSETiStFD11_SigSts
      VeSR1B_y_ISO15118_MsgRespFD11: nonqueued-receiver-com-spec{data-element=Value, handle-never-received=true, init-value=0}, required-interface=VeSR1B_y_ISO15118_MsgRespFD11
      VeSR1B_y_ISO15118_MsgRespFD11_SigSts: nonqueued-receiver-com-spec{data-element=Value, init-value=0}, required-interface=VeSR1B_y_ISO15118_MsgRespFD11_SigSts
      VeSR1B_t_ISO15118NtfcnMxDlyFD11: nonqueued-receiver-com-spec{data-element=Value, handle-never-received=true, init-value=0}, required-interface=VeSR1B_t_ISO15118NtfcnMxDlyFD11
      VeSR1B_y_ISO15118NtfcnMxDlyFD11_SigSts: nonqueued-receiver-com-spec{data-element=Value, init-value=0}, required-interface=VeSR1B_y_ISO15118NtfcnMxDlyFD11_SigSts
      VeSR1B_y_ISO15118_RespCodFD11: nonqueued-receiver-com-spec{data-element=Value, handle-never-received=true, init-value=0}, required-interface=VeSR1B_y_ISO15118_RespCodFD11
      VeSR1B_y_ISO15118_RespCodFD11_SigSts: nonqueued-receiver-com-spec{data-element=Value, init-value=0}, required-interface=VeSR1B_y_ISO15118_RespCodFD11_SigSts
      VeSR1B_y_ISO15118SAScdlTlIDFD11: nonqueued-receiver-com-spec{data-element=Value, handle-never-received=true, init-value=0}, required-interface=VeSR1B_y_ISO15118SAScdlTlIDFD11
      VeSR1B_y_ISO15118SAScdlTlIDFD11_SigSts: nonqueued-receiver-com-spec{data-element=Value, init-value=0}, required-interface=VeSR1B_y_ISO15118SAScdlTlIDFD11_SigSts
      VeSR1B_y_ISO15118_SchemaID_FD11: nonqueued-receiver-com-spec{data-element=Value, handle-never-received=true, init-value=0}, required-interface=VeSR1B_y_ISO15118_SchemaID_FD11
      VeSR1B_y_ISO15118_SchemaID_FD11_SigSts: nonqueued-receiver-com-spec{data-element=Value, init-value=0}, required-interface=VeSR1B_y_ISO15118_SchemaID_FD11_SigSts
      VeSR1B_d_ISO15118_ServiceIDFD11: nonqueued-receiver-com-spec{data-element=Value, handle-never-received=true, init-value=0}, required-interface=VeSR1B_d_ISO15118_ServiceIDFD11
      VeSR1B_y_ISO15118_ServiceIDFD11_SigSts: nonqueued-receiver-com-spec{data-element=Value, init-value=0}, required-interface=VeSR1B_y_ISO15118_ServiceIDFD11_SigSts
      VeSR1B_b_ISO15118_TLSoffrdFD11: nonqueued-receiver-com-spec{data-element=Value, handle-never-received=true, init-value=0}, required-interface=VeSR1B_b_ISO15118_TLSoffrdFD11
      VeSR1B_y_ISO15118_TLSoffrdFD11_SigSts: nonqueued-receiver-com-spec{data-element=Value, init-value=0}, required-interface=VeSR1B_y_ISO15118_TLSoffrdFD11_SigSts
      VeSR1B_y_ISO15118_TLSStatusFD11: nonqueued-receiver-com-spec{data-element=Value, handle-never-received=true, init-value=0}, required-interface=VeSR1B_y_ISO15118_TLSStatusFD11
      VeSR1B_y_ISO15118_TLSStatusFD11_SigSts: nonqueued-receiver-com-spec{data-element=Value, init-value=0}, required-interface=VeSR1B_y_ISO15118_TLSStatusFD11_SigSts
      VeSR1B_y_ISO15118VrsnNmMajrFD11: nonqueued-receiver-com-spec{data-element=Value, handle-never-received=true, init-value=0}, required-interface=VeSR1B_y_ISO15118VrsnNmMajrFD11
      VeSR1B_y_ISO15118VrsnNmMajrFD11_SigSts: nonqueued-receiver-com-spec{data-element=Value, init-value=0}, required-interface=VeSR1B_y_ISO15118VrsnNmMajrFD11_SigSts
      VeSR1B_y_ISO15118VrsnNmMinrFD11: nonqueued-receiver-com-spec{data-element=Value, handle-never-received=true, init-value=0}, required-interface=VeSR1B_y_ISO15118VrsnNmMinrFD11
      VeSR1B_y_ISO15118VrsnNmMinrFD11_SigSts: nonqueued-receiver-com-spec{data-element=Value, init-value=0}, required-interface=VeSR1B_y_ISO15118VrsnNmMinrFD11_SigSts
      VeSR1B_b_V2X_EVSE_Service5_Free: nonqueued-receiver-com-spec{data-element=Value, handle-never-received=true, init-value=0}, required-interface=VeSR1B_b_V2X_EVSE_Service5_Free
      VeSR1B_y_V2X_EVSE_Service5_Free_SigSts: nonqueued-receiver-com-spec{data-element=Value, init-value=0}, required-interface=VeSR1B_y_V2X_EVSE_Service5_Free_SigSts
      VeCRDB_b_DC_Isoln_Dsbl_Cmd: nonqueued-receiver-com-spec{data-element=Value, handle-never-received=true, init-value=0}, required-interface=VeCRDB_b_DC_Isoln_Dsbl_Cmd
      VeCRDB_y_DC_Isoln_Dsbl_Cmd_SigSts: nonqueued-receiver-com-spec{data-element=Value, init-value=0}, required-interface=VeCRDB_y_DC_Isoln_Dsbl_Cmd_SigSts
      VeCRDB_b_DC_TimeOut: nonqueued-receiver-com-spec{data-element=Value, handle-never-received=true, init-value=0}, required-interface=VeCRDB_b_DC_TimeOut
      VeCRDB_y_DC_TimeOut_SigSts: nonqueued-receiver-com-spec{data-element=Value, init-value=0}, required-interface=VeCRDB_y_DC_TimeOut_SigSts
      VeCRDB_d_EVSE_Acptd_Prtcl: nonqueued-receiver-com-spec{data-element=Value, handle-never-received=true, init-value=0}, required-interface=VeCRDB_d_EVSE_Acptd_Prtcl
      VeCRDB_y_EVSE_Acptd_Prtcl_SigSts: nonqueued-receiver-com-spec{data-element=Value, init-value=0}, required-interface=VeCRDB_y_EVSE_Acptd_Prtcl_SigSts
      VeCRDB_b_EVSE_FreeService: nonqueued-receiver-com-spec{data-element=Value, handle-never-received=true, init-value=0}, required-interface=VeCRDB_b_EVSE_FreeService
      VeCRDB_y_EVSE_FreeService_SigSts: nonqueued-receiver-com-spec{data-element=Value, init-value=0}, required-interface=VeCRDB_y_EVSE_FreeService_SigSts
      VeCRDB_y_EVSE_IsolationSts: nonqueued-receiver-com-spec{data-element=Value, handle-never-received=true, init-value=0}, required-interface=VeCRDB_y_EVSE_IsolationSts
      VeCRDB_y_EVSE_IsolationSts_SigSts: nonqueued-receiver-com-spec{data-element=Value, init-value=0}, required-interface=VeCRDB_y_EVSE_IsolationSts_SigSts
      VeCRDB_y_EVSE_Notification: nonqueued-receiver-com-spec{data-element=Value, handle-never-received=true, init-value=0}, required-interface=VeCRDB_y_EVSE_Notification
      VeCRDB_y_EVSE_Notification_SigSts: nonqueued-receiver-com-spec{data-element=Value, init-value=0}, required-interface=VeCRDB_y_EVSE_Notification_SigSts
      VeCRDB_y_EVSEOfrdEgyTrfTyp: nonqueued-receiver-com-spec{data-element=Value, handle-never-received=true, init-value=0}, required-interface=VeCRDB_y_EVSEOfrdEgyTrfTyp
      VeCRDB_y_EVSEOfrdEgyTrfTyp_SigSts: nonqueued-receiver-com-spec{data-element=Value, init-value=0}, required-interface=VeCRDB_y_EVSEOfrdEgyTrfTyp_SigSts
      VeCRDB_b_EVSE_OfdPymtCntct: nonqueued-receiver-com-spec{data-element=Value, handle-never-received=true, init-value=0}, required-interface=VeCRDB_b_EVSE_OfdPymtCntct
      VeCRDB_y_EVSE_OfdPymtCntct_SigSts: nonqueued-receiver-com-spec{data-element=Value, init-value=0}, required-interface=VeCRDB_y_EVSE_OfdPymtCntct_SigSts
      VeCRDB_b_EVSE_OfrdPymntEIM: nonqueued-receiver-com-spec{data-element=Value, handle-never-received=true, init-value=0}, required-interface=VeCRDB_b_EVSE_OfrdPymntEIM
      VeCRDB_y_EVSE_OfrdPymntEIM_SigSts: nonqueued-receiver-com-spec{data-element=Value, init-value=0}, required-interface=VeCRDB_y_EVSE_OfrdPymntEIM_SigSts
      VeCRDB_y_EVSE_OfrdPmtOptn: nonqueued-receiver-com-spec{data-element=Value, handle-never-received=true, init-value=0}, required-interface=VeCRDB_y_EVSE_OfrdPmtOptn
      VeCRDB_y_EVSE_OfrdPmtOptn_SigSts: nonqueued-receiver-com-spec{data-element=Value, init-value=0}, required-interface=VeCRDB_y_EVSE_OfrdPmtOptn_SigSts
      VeCRDB_y_EVSE_OfrdServ: nonqueued-receiver-com-spec{data-element=Value, handle-never-received=true, init-value=0}, required-interface=VeCRDB_y_EVSE_OfrdServ
      VeCRDB_y_EVSE_OfrdServ_SigSts: nonqueued-receiver-com-spec{data-element=Value, init-value=0}, required-interface=VeCRDB_y_EVSE_OfrdServ_SigSts
      VeCRDB_b_EVSE_Srvc2Crtfct: nonqueued-receiver-com-spec{data-element=Value, handle-never-received=true, init-value=0}, required-interface=VeCRDB_b_EVSE_Srvc2Crtfct
      VeCRDB_y_EVSE_Srvc2Crtfct_SigSts: nonqueued-receiver-com-spec{data-element=Value, init-value=0}, required-interface=VeCRDB_y_EVSE_Srvc2Crtfct_SigSts
      VeCRDB_d_EVSE_ServiceId: nonqueued-receiver-com-spec{data-element=Value, handle-never-received=true, init-value=0}, required-interface=VeCRDB_d_EVSE_ServiceId
      VeCRDB_y_EVSE_ServiceId_SigSts: nonqueued-receiver-com-spec{data-element=Value, init-value=0}, required-interface=VeCRDB_y_EVSE_ServiceId_SigSts
      VeCRDB_b_EVSE_Supportd_DIN: nonqueued-receiver-com-spec{data-element=Value, handle-never-received=true, init-value=0}, required-interface=VeCRDB_b_EVSE_Supportd_DIN
      VeCRDB_y_EVSE_Supportd_DIN_SigSts: nonqueued-receiver-com-spec{data-element=Value, init-value=0}, required-interface=VeCRDB_y_EVSE_Supportd_DIN_SigSts
      VeCRDB_b_EVSE_Supprtd_ISO1: nonqueued-receiver-com-spec{data-element=Value, handle-never-received=true, init-value=0}, required-interface=VeCRDB_b_EVSE_Supprtd_ISO1
      VeCRDB_y_EVSE_Supprtd_ISO1_SigSts: nonqueued-receiver-com-spec{data-element=Value, init-value=0}, required-interface=VeCRDB_y_EVSE_Supprtd_ISO1_SigSts
      VeCRDB_I_HVCMS_EVSECurRglTl: nonqueued-receiver-com-spec{data-element=Value, handle-never-received=true, init-value=0}, required-interface=VeCRDB_I_HVCMS_EVSECurRglTl
      VeCRDB_y_HVCMS_EVSECurRglTl_SigSts: nonqueued-receiver-com-spec{data-element=Value, init-value=0}, required-interface=VeCRDB_y_HVCMS_EVSECurRglTl_SigSts
      VeCRDB_y_HVCMS_EVSECurLmAch: nonqueued-receiver-com-spec{data-element=Value, handle-never-received=true, init-value=0}, required-interface=VeCRDB_y_HVCMS_EVSECurLmAch
      VeCRDB_y_HVCMS_EVSECurLmAch_SigSts: nonqueued-receiver-com-spec{data-element=Value, init-value=0}, required-interface=VeCRDB_y_HVCMS_EVSECurLmAch_SigSts
      VeCRDB_I_HVCMS_EVSEMaxCurLm: nonqueued-receiver-com-spec{data-element=Value, handle-never-received=true, init-value=0}, required-interface=VeCRDB_I_HVCMS_EVSEMaxCurLm
      VeCRDB_y_HVCMS_EVSEMaxCurLm_SigSts: nonqueued-receiver-com-spec{data-element=Value, init-value=0}, required-interface=VeCRDB_y_HVCMS_EVSEMaxCurLm_SigSts
      VeCRDB_W_HVCMS_EVSEMaxPwrLm: nonqueued-receiver-com-spec{data-element=Value, handle-never-received=true, init-value=0}, required-interface=VeCRDB_W_HVCMS_EVSEMaxPwrLm
      VeCRDB_y_HVCMS_EVSEMaxPwrLm_SigSts: nonqueued-receiver-com-spec{data-element=Value, init-value=0}, required-interface=VeCRDB_y_HVCMS_EVSEMaxPwrLm_SigSts
      VeCRDB_U_HVCMS_EVSEMaxVltLm: nonqueued-receiver-com-spec{data-element=Value, handle-never-received=true, init-value=0}, required-interface=VeCRDB_U_HVCMS_EVSEMaxVltLm
      VeCRDB_y_HVCMS_EVSEMaxVltLm_SigSts: nonqueued-receiver-com-spec{data-element=Value, init-value=0}, required-interface=VeCRDB_y_HVCMS_EVSEMaxVltLm_SigSts
      VeCRDB_I_HVCMS_EVSEMinCurLm: nonqueued-receiver-com-spec{data-element=Value, handle-never-received=true, init-value=0}, required-interface=VeCRDB_I_HVCMS_EVSEMinCurLm
      VeCRDB_y_HVCMS_EVSEMinCurLm_SigSts: nonqueued-receiver-com-spec{data-element=Value, init-value=0}, required-interface=VeCRDB_y_HVCMS_EVSEMinCurLm_SigSts
      VeCRDB_U_HVCMS_EVSEMinVltLm: nonqueued-receiver-com-spec{data-element=Value, handle-never-received=true, init-value=0}, required-interface=VeCRDB_U_HVCMS_EVSEMinVltLm
      VeCRDB_y_HVCMS_EVSEMinVltLm_SigSts: nonqueued-receiver-com-spec{data-element=Value, init-value=0}, required-interface=VeCRDB_y_HVCMS_EVSEMinVltLm_SigSts
      VeCRDB_I_HVCMS_EVSEPkCurRpl: nonqueued-receiver-com-spec{data-element=Value, handle-never-received=true, init-value=0}, required-interface=VeCRDB_I_HVCMS_EVSEPkCurRpl
      VeCRDB_y_HVCMS_EVSEPkCurRpl_SigSts: nonqueued-receiver-com-spec{data-element=Value, init-value=0}, required-interface=VeCRDB_y_HVCMS_EVSEPkCurRpl_SigSts
      VeCRDB_y_HVCMS_EVSEPwrLmAch: nonqueued-receiver-com-spec{data-element=Value, handle-never-received=true, init-value=0}, required-interface=VeCRDB_y_HVCMS_EVSEPwrLmAch
      VeCRDB_y_HVCMS_EVSEPwrLmAch_SigSts: nonqueued-receiver-com-spec{data-element=Value, init-value=0}, required-interface=VeCRDB_y_HVCMS_EVSEPwrLmAch_SigSts
      VeCRDB_I_HVCMS_EVSEPrsntCur: nonqueued-receiver-com-spec{data-element=Value, handle-never-received=true, init-value=0}, required-interface=VeCRDB_I_HVCMS_EVSEPrsntCur
      VeCRDB_y_HVCMS_EVSEPrsntCur_SigSts: nonqueued-receiver-com-spec{data-element=Value, init-value=0}, required-interface=VeCRDB_y_HVCMS_EVSEPrsntCur_SigSts
      VeCRDB_U_HVCMS_EVSEPrsntVlt: nonqueued-receiver-com-spec{data-element=Value, handle-never-received=true, init-value=0}, required-interface=VeCRDB_U_HVCMS_EVSEPrsntVlt
      VeCRDB_y_HVCMS_EVSEPrsntVlt_SigSts: nonqueued-receiver-com-spec{data-element=Value, init-value=0}, required-interface=VeCRDB_y_HVCMS_EVSEPrsntVlt_SigSts
      VeCRDB_b_HVCMS_EVSEProcg: nonqueued-receiver-com-spec{data-element=Value, handle-never-received=true, init-value=0}, required-interface=VeCRDB_b_HVCMS_EVSEProcg
      VeCRDB_y_HVCMS_EVSEProcg_SigSts: nonqueued-receiver-com-spec{data-element=Value, init-value=0}, required-interface=VeCRDB_y_HVCMS_EVSEProcg_SigSts
      VeCRDB_y_HVCMS_EVSEStsCod: nonqueued-receiver-com-spec{data-element=Value, handle-never-received=true, init-value=0}, required-interface=VeCRDB_y_HVCMS_EVSEStsCod
      VeCRDB_y_HVCMS_EVSEStsCod_SigSts: nonqueued-receiver-com-spec{data-element=Value, init-value=0}, required-interface=VeCRDB_y_HVCMS_EVSEStsCod_SigSts
      VeCRDB_y_HVCMS_EVSEVltLmAch: nonqueued-receiver-com-spec{data-element=Value, handle-never-received=true, init-value=0}, required-interface=VeCRDB_y_HVCMS_EVSEVltLmAch
      VeCRDB_y_HVCMS_EVSEVltLmAch_SigSts: nonqueued-receiver-com-spec{data-element=Value, init-value=0}, required-interface=VeCRDB_y_HVCMS_EVSEVltLmAch_SigSts
      VeCRDB_EWhr_HVCMS_EgToBDlvd: nonqueued-receiver-com-spec{data-element=Value, handle-never-received=true, init-value=0}, required-interface=VeCRDB_EWhr_HVCMS_EgToBDlvd
      VeCRDB_y_HVCMS_EgToBDlvd_SigSts: nonqueued-receiver-com-spec{data-element=Value, init-value=0}, required-interface=VeCRDB_y_HVCMS_EgToBDlvd_SigSts
      VeCRDB_y_HVCMS_ResponseCode: nonqueued-receiver-com-spec{data-element=Value, handle-never-received=true, init-value=0}, required-interface=VeCRDB_y_HVCMS_ResponseCode
      VeCRDB_y_HVCMS_ResponseCode_SigSts: nonqueued-receiver-com-spec{data-element=Value, init-value=0}, required-interface=VeCRDB_y_HVCMS_ResponseCode_SigSts
      VeCRDB_y_HVCMS_TxMsgStat: nonqueued-receiver-com-spec{data-element=Value, handle-never-received=true, init-value=0}, required-interface=VeCRDB_y_HVCMS_TxMsgStat
      VeCRDB_y_HVCMS_TxMsgStat_SigSts: nonqueued-receiver-com-spec{data-element=Value, init-value=0}, required-interface=VeCRDB_y_HVCMS_TxMsgStat_SigSts
      VeCRDB_y_OBCM_PLCTypeSts: nonqueued-receiver-com-spec{data-element=Value, handle-never-received=true, init-value=0}, required-interface=VeCRDB_y_OBCM_PLCTypeSts
      VeCRDB_y_OBCM_PLCTypeSts_SigSts: nonqueued-receiver-com-spec{data-element=Value, init-value=0}, required-interface=VeCRDB_y_OBCM_PLCTypeSts_SigSts
      VeCRDB_b_ReceiptRequired: nonqueued-receiver-com-spec{data-element=Value, handle-never-received=true, init-value=0}, required-interface=VeCRDB_b_ReceiptRequired
      VeCRDB_y_ReceiptRequired_SigSts: nonqueued-receiver-com-spec{data-element=Value, init-value=0}, required-interface=VeCRDB_y_ReceiptRequired_SigSts
      VeSR1B_b_V2X_EVSE_Service_5_V2H: nonqueued-receiver-com-spec{data-element=Value, handle-never-received=true, init-value=0}, required-interface=VeSR1B_b_V2X_EVSE_Service_5_V2H
      VeSR1B_y_V2X_EVSE_Service_5_V2H_SigSts: nonqueued-receiver-com-spec{data-element=Value, init-value=0}, required-interface=VeSR1B_y_V2X_EVSE_Service_5_V2H_SigSts
      VeCRDB_y_ChargerFaultStates: nonqueued-receiver-com-spec{data-element=Value, handle-never-received=true, init-value=0}, required-interface=VeCRDB_y_ChargerFaultStates
      VeCRDB_y_ChargerFaultStates_SigSts: nonqueued-receiver-com-spec{data-element=Value, init-value=0}, required-interface=VeCRDB_y_ChargerFaultStates_SigSts
      VeCRDB_y_ChrgrWldDtctAvail: nonqueued-receiver-com-spec{data-element=Value, handle-never-received=true, init-value=0}, required-interface=VeCRDB_y_ChrgrWldDtctAvail
      VeCRDB_y_ChrgrWldDtctAvail_SigSts: nonqueued-receiver-com-spec{data-element=Value, init-value=0}, required-interface=VeCRDB_y_ChrgrWldDtctAvail_SigSts
      VeCRDB_b_EVCC_FailureSts: nonqueued-receiver-com-spec{data-element=Value, handle-never-received=true, init-value=0}, required-interface=VeCRDB_b_EVCC_FailureSts
      VeCRDB_y_EVCC_FailureSts_SigSts: nonqueued-receiver-com-spec{data-element=Value, init-value=0}, required-interface=VeCRDB_y_EVCC_FailureSts_SigSts
      VeCRDB_y_EVSE_ChrgStopCtrl: nonqueued-receiver-com-spec{data-element=Value, handle-never-received=true, init-value=0}, required-interface=VeCRDB_y_EVSE_ChrgStopCtrl
      VeCRDB_y_EVSE_ChrgStopCtrl_SigSts: nonqueued-receiver-com-spec{data-element=Value, init-value=0}, required-interface=VeCRDB_y_EVSE_ChrgStopCtrl_SigSts
      VeCRDB_y_EVSE_Error: nonqueued-receiver-com-spec{data-element=Value, handle-never-received=true, init-value=0}, required-interface=VeCRDB_y_EVSE_Error
      VeCRDB_y_EVSE_Error_SigSts: nonqueued-receiver-com-spec{data-element=Value, init-value=0}, required-interface=VeCRDB_y_EVSE_Error_SigSts
      VeCRDB_t_EVSE_NtfcnMaxDly: nonqueued-receiver-com-spec{data-element=Value, handle-never-received=true, init-value=0}, required-interface=VeCRDB_t_EVSE_NtfcnMaxDly
      VeCRDB_y_EVSE_NtfcnMaxDly_SigSts: nonqueued-receiver-com-spec{data-element=Value, init-value=0}, required-interface=VeCRDB_y_EVSE_NtfcnMaxDly_SigSts
      VeCRDB_y_ExtChargerSts: nonqueued-receiver-com-spec{data-element=Value, handle-never-received=true, init-value=0}, required-interface=VeCRDB_y_ExtChargerSts
      VeCRDB_y_ExtChargerSts_SigSts: nonqueued-receiver-com-spec{data-element=Value, init-value=0}, required-interface=VeCRDB_y_ExtChargerSts_SigSts
      VeCRDB_g_HVCMS_EVSEID: nonqueued-receiver-com-spec{data-element=Value, handle-never-received=true, init-value=0}, required-interface=VeCRDB_g_HVCMS_EVSEID
      VeCRDB_y_HVCMS_EVSEID_SigSts: nonqueued-receiver-com-spec{data-element=Value, init-value=0}, required-interface=VeCRDB_y_HVCMS_EVSEID_SigSts
      VeCRDB_y_OBCM_CCSts: nonqueued-receiver-com-spec{data-element=Value, handle-never-received=true, init-value=0}, required-interface=VeCRDB_y_OBCM_CCSts
      VeCRDB_y_OBCM_CCSts_SigSts: nonqueued-receiver-com-spec{data-element=Value, init-value=0}, required-interface=VeCRDB_y_OBCM_CCSts_SigSts
      VeCRDB_y_OBCM_CP1Sts: nonqueued-receiver-com-spec{data-element=Value, handle-never-received=true, init-value=0}, required-interface=VeCRDB_y_OBCM_CP1Sts
      VeCRDB_y_OBCM_CP1Sts_SigSts: nonqueued-receiver-com-spec{data-element=Value, init-value=0}, required-interface=VeCRDB_y_OBCM_CP1Sts_SigSts
      VeCRDB_y_OBCM_CP2Sts: nonqueued-receiver-com-spec{data-element=Value, handle-never-received=true, init-value=0}, required-interface=VeCRDB_y_OBCM_CP2Sts
      VeCRDB_y_OBCM_CP2Sts_SigSts: nonqueued-receiver-com-spec{data-element=Value, init-value=0}, required-interface=VeCRDB_y_OBCM_CP2Sts_SigSts
      VeCRDB_y_OBCM_CP3Sts: nonqueued-receiver-com-spec{data-element=Value, handle-never-received=true, init-value=0}, required-interface=VeCRDB_y_OBCM_CP3Sts
      VeCRDB_y_OBCM_CP3Sts_SigSts: nonqueued-receiver-com-spec{data-element=Value, init-value=0}, required-interface=VeCRDB_y_OBCM_CP3Sts_SigSts
      VeCRDB_y_OBCM_CSSts: nonqueued-receiver-com-spec{data-element=Value, handle-never-received=true, init-value=0}, required-interface=VeCRDB_y_OBCM_CSSts
      VeCRDB_y_OBCM_CSSts_SigSts: nonqueued-receiver-com-spec{data-element=Value, init-value=0}, required-interface=VeCRDB_y_OBCM_CSSts_SigSts
      VeCRDB_b_OBCM_Timeout: nonqueued-receiver-com-spec{data-element=Value, handle-never-received=true, init-value=0}, required-interface=VeCRDB_b_OBCM_Timeout
      VeCRDB_y_OBCM_Timeout_SigSts: nonqueued-receiver-com-spec{data-element=Value, init-value=0}, required-interface=VeCRDB_y_OBCM_Timeout_SigSts
      VeCRDB_b_TCP_ComTerminated: nonqueued-receiver-com-spec{data-element=Value, handle-never-received=true, init-value=0}, required-interface=VeCRDB_b_TCP_ComTerminated
      VeCRDB_y_TCP_ComTerminated_SigSts: nonqueued-receiver-com-spec{data-element=Value, init-value=0}, required-interface=VeCRDB_y_TCP_ComTerminated_SigSts
      VeSR1B_I_ACOutputCurrent1: nonqueued-receiver-com-spec{data-element=Value, handle-never-received=true, init-value=0}, required-interface=VeSR1B_I_ACOutputCurrent1
      VeSR1B_y_ACOutputCurrent1_SigSts: nonqueued-receiver-com-spec{data-element=Value, init-value=0}, required-interface=VeSR1B_y_ACOutputCurrent1_SigSts
      VeSR1B_I_ACOutputCurrent2: nonqueued-receiver-com-spec{data-element=Value, handle-never-received=true, init-value=0}, required-interface=VeSR1B_I_ACOutputCurrent2
      VeSR1B_y_ACOutputCurrent2_SigSts: nonqueued-receiver-com-spec{data-element=Value, init-value=0}, required-interface=VeSR1B_y_ACOutputCurrent2_SigSts
      VeSR1B_I_ACOutputCurrent3: nonqueued-receiver-com-spec{data-element=Value, handle-never-received=true, init-value=0}, required-interface=VeSR1B_I_ACOutputCurrent3
      VeSR1B_y_ACOutputCurrent3_SigSts: nonqueued-receiver-com-spec{data-element=Value, init-value=0}, required-interface=VeSR1B_y_ACOutputCurrent3_SigSts
      VeSR1B_U_ACOutputVoltage1: nonqueued-receiver-com-spec{data-element=Value, handle-never-received=true, init-value=0}, required-interface=VeSR1B_U_ACOutputVoltage1
      VeSR1B_y_ACOutputVoltage1_SigSts: nonqueued-receiver-com-spec{data-element=Value, init-value=0}, required-interface=VeSR1B_y_ACOutputVoltage1_SigSts
      VeSR1B_U_ACOutputVoltage2: nonqueued-receiver-com-spec{data-element=Value, handle-never-received=true, init-value=0}, required-interface=VeSR1B_U_ACOutputVoltage2
      VeSR1B_y_ACOutputVoltage2_SigSts: nonqueued-receiver-com-spec{data-element=Value, init-value=0}, required-interface=VeSR1B_y_ACOutputVoltage2_SigSts
      VeSR1B_U_ACOutputVoltage3: nonqueued-receiver-com-spec{data-element=Value, handle-never-received=true, init-value=0}, required-interface=VeSR1B_U_ACOutputVoltage3
      VeSR1B_y_ACOutputVoltage3_SigSts: nonqueued-receiver-com-spec{data-element=Value, init-value=0}, required-interface=VeSR1B_y_ACOutputVoltage3_SigSts
      VeSR1B_y_ACOutput_Frequency: nonqueued-receiver-com-spec{data-element=Value, handle-never-received=true, init-value=0}, required-interface=VeSR1B_y_ACOutput_Frequency
      VeSR1B_y_ACOutput_Frequency_SigSts: nonqueued-receiver-com-spec{data-element=Value, init-value=0}, required-interface=VeSR1B_y_ACOutput_Frequency_SigSts
      VeSR1B_I_DCInputCurrent: nonqueued-receiver-com-spec{data-element=Value, handle-never-received=true, init-value=0}, required-interface=VeSR1B_I_DCInputCurrent
      VeSR1B_y_DCInputCurrent_SigSts: nonqueued-receiver-com-spec{data-element=Value, init-value=0}, required-interface=VeSR1B_y_DCInputCurrent_SigSts
      VeSR1B_U_DCInputVoltage: nonqueued-receiver-com-spec{data-element=Value, handle-never-received=true, init-value=0}, required-interface=VeSR1B_U_DCInputVoltage
      VeSR1B_y_DCInputVoltage_SigSts: nonqueued-receiver-com-spec{data-element=Value, init-value=0}, required-interface=VeSR1B_y_DCInputVoltage_SigSts
      VeSR1B_y_DischargeFaultStatus: nonqueued-receiver-com-spec{data-element=Value, handle-never-received=true, init-value=0}, required-interface=VeSR1B_y_DischargeFaultStatus
      VeSR1B_y_DischargeFaultStatus_SigSts: nonqueued-receiver-com-spec{data-element=Value, init-value=0}, required-interface=VeSR1B_y_DischargeFaultStatus_SigSts
      VeSR1B_b_IDCM_GFCI_Fault_Status: variation-point={short-label=vpVeSR1B_b_IDCM_GFCI_Fault_Status, sw-syscond=1}, nonqueued-receiver-com-spec{data-element=Value, handle-never-received=true, init-value=0}, required-interface=VeSR1B_b_IDCM_GFCI_Fault_Status
      VeSR1B_y_IDCM_GFCI_Fault_Status_SigSts: variation-point={short-label=vpVeSR1B_y_IDCM_GFCI_Fault_Status_SigSts, sw-syscond=1}, nonqueued-receiver-com-spec{data-element=Value, init-value=0}, required-interface=VeSR1B_y_IDCM_GFCI_Fault_Status_SigSts
      VeSR1B_P_V2X_Frequency: nonqueued-receiver-com-spec{data-element=Value, handle-never-received=true, init-value=0}, required-interface=VeSR1B_P_V2X_Frequency
      VeSR1B_y_V2X_Frequency_SigSts: nonqueued-receiver-com-spec{data-element=Value, init-value=0}, required-interface=VeSR1B_y_V2X_Frequency_SigSts
      VeSR1B_y_V2X_Status: nonqueued-receiver-com-spec{data-element=Value, handle-never-received=true, init-value=0}, required-interface=VeSR1B_y_V2X_Status
      VeSR1B_y_V2X_Status_SigSts: nonqueued-receiver-com-spec{data-element=Value, init-value=0}, required-interface=VeSR1B_y_V2X_Status_SigSts
      VeSR1B_I_AcOuputCurrent: nonqueued-receiver-com-spec{data-element=Value, handle-never-received=true, init-value=0}, required-interface=VeSR1B_I_AcOuputCurrent
      VeSR1B_y_AcOuputCurrent_SigSts: nonqueued-receiver-com-spec{data-element=Value, init-value=0}, required-interface=VeSR1B_y_AcOuputCurrent_SigSts
      VeSR1B_I_AcOutputFrequency: nonqueued-receiver-com-spec{data-element=Value, handle-never-received=true, init-value=0}, required-interface=VeSR1B_I_AcOutputFrequency
      VeSR1B_y_AcOutputFrequency_SigSts: nonqueued-receiver-com-spec{data-element=Value, init-value=0}, required-interface=VeSR1B_y_AcOutputFrequency_SigSts
      VeSR1B_U_AcOutputVoltage: nonqueued-receiver-com-spec{data-element=Value, handle-never-received=true, init-value=0}, required-interface=VeSR1B_U_AcOutputVoltage
      VeSR1B_y_AcOutputVoltage_SigSts: nonqueued-receiver-com-spec{data-element=Value, init-value=0}, required-interface=VeSR1B_y_AcOutputVoltage_SigSts
      VeSR1B_P_Available_Power: nonqueued-receiver-com-spec{data-element=Value, handle-never-received=true, init-value=0}, required-interface=VeSR1B_P_Available_Power
      VeSR1B_y_Available_Power_SigSts: nonqueued-receiver-com-spec{data-element=Value, init-value=0}, required-interface=VeSR1B_y_Available_Power_SigSts
      VeSR1B_y_V2X_Derate_Reason: nonqueued-receiver-com-spec{data-element=Value, handle-never-received=true, init-value=0}, required-interface=VeSR1B_y_V2X_Derate_Reason
      VeSR1B_y_V2X_Derate_Reason_SigSts: nonqueued-receiver-com-spec{data-element=Value, init-value=0}, required-interface=VeSR1B_y_V2X_Derate_Reason_SigSts
      VeSR1B_b_V2X_Derate_Status: nonqueued-receiver-com-spec{data-element=Value, handle-never-received=true, init-value=0}, required-interface=VeSR1B_b_V2X_Derate_Status
      VeSR1B_y_V2X_Derate_Status_SigSts: nonqueued-receiver-com-spec{data-element=Value, init-value=0}, required-interface=VeSR1B_y_V2X_Derate_Status_SigSts
      VeSR1B_b_V2X_FailSts: nonqueued-receiver-com-spec{data-element=Value, handle-never-received=true, init-value=0}, required-interface=VeSR1B_b_V2X_FailSts
      VeSR1B_y_V2X_FailSts_SigSts: nonqueued-receiver-com-spec{data-element=Value, init-value=0}, required-interface=VeSR1B_y_V2X_FailSts_SigSts
      VeSR1B_y_V2X_FaultRsn: nonqueued-receiver-com-spec{data-element=Value, handle-never-received=true, init-value=0}, required-interface=VeSR1B_y_V2X_FaultRsn
      VeSR1B_y_V2X_FaultRsn_SigSts: nonqueued-receiver-com-spec{data-element=Value, init-value=0}, required-interface=VeSR1B_y_V2X_FaultRsn_SigSts
      VeSR1B_I_V2X_InputCurrent: nonqueued-receiver-com-spec{data-element=Value, handle-never-received=true, init-value=0}, required-interface=VeSR1B_I_V2X_InputCurrent
      VeSR1B_y_V2X_InputCurrent_SigSts: nonqueued-receiver-com-spec{data-element=Value, init-value=0}, required-interface=VeSR1B_y_V2X_InputCurrent_SigSts
      VeSR1B_U_V2X_InputVoltage: nonqueued-receiver-com-spec{data-element=Value, handle-never-received=true, init-value=0}, required-interface=VeSR1B_U_V2X_InputVoltage
      VeSR1B_y_V2X_InputVoltage_SigSts: nonqueued-receiver-com-spec{data-element=Value, init-value=0}, required-interface=VeSR1B_y_V2X_InputVoltage_SigSts
      VeSR1B_y_V2X_InterlockSts: nonqueued-receiver-com-spec{data-element=Value, handle-never-received=true, init-value=0}, required-interface=VeSR1B_y_V2X_InterlockSts
      VeSR1B_y_V2X_InterlockSts_SigSts: nonqueued-receiver-com-spec{data-element=Value, init-value=0}, required-interface=VeSR1B_y_V2X_InterlockSts_SigSts
      VeSR1B_U_V2X_LV_Feed: nonqueued-receiver-com-spec{data-element=Value, handle-never-received=true, init-value=0}, required-interface=VeSR1B_U_V2X_LV_Feed
      VeSR1B_y_V2X_LV_Feed_SigSts: nonqueued-receiver-com-spec{data-element=Value, init-value=0}, required-interface=VeSR1B_y_V2X_LV_Feed_SigSts
      VeSR1B_y_V2X_Modefeedback: nonqueued-receiver-com-spec{data-element=Value, handle-never-received=true, init-value=0}, required-interface=VeSR1B_y_V2X_Modefeedback
      VeSR1B_y_V2X_Modefeedback_SigSts: nonqueued-receiver-com-spec{data-element=Value, init-value=0}, required-interface=VeSR1B_y_V2X_Modefeedback_SigSts
      FsftIDCR_e_APM2InterlockSts: client-com-spec=FsftIDCR_e_APM2InterlockSts, required-interface=FsftIDCR_e_APM2InterlockSts
      PokeIDCR_e_APM2InterlockSts: client-com-spec=PokeIDCR_e_APM2InterlockSts, required-interface=PokeIDCR_e_APM2InterlockSts
      PokeIDCR_e_stModeRqAPM: client-com-spec=PokeIDCR_e_stModeRqAPM, required-interface=PokeIDCR_e_stModeRqAPM
      PokeIDCR_b_HvTooHighIStatus: client-com-spec=PokeIDCR_b_HvTooHighIStatus, required-interface=PokeIDCR_b_HvTooHighIStatus
      PokeIDCR_e_APM_DeratingModeStatus: client-com-spec=PokeIDCR_e_APM_DeratingModeStatus, required-interface=PokeIDCR_e_APM_DeratingModeStatus
      PokeIDCR_P_APM_DeratingPower: client-com-spec=PokeIDCR_P_APM_DeratingPower, required-interface=PokeIDCR_P_APM_DeratingPower
      PokeIDCR_e_APM_DeratingReason: client-com-spec=PokeIDCR_e_APM_DeratingReason, required-interface=PokeIDCR_e_APM_DeratingReason
      FsftIDCR_P_APM_PwrLoss: client-com-spec=FsftIDCR_P_APM_PwrLoss, required-interface=FsftIDCR_P_APM_PwrLoss
      PokeIDCR_P_APM_PwrLoss: client-com-spec=PokeIDCR_P_APM_PwrLoss, required-interface=PokeIDCR_P_APM_PwrLoss
      PokeIDCR_e_APM_FailureReason: client-com-spec=PokeIDCR_e_APM_FailureReason, required-interface=PokeIDCR_e_APM_FailureReason
      PokeIDCR_e_APM_FailureType: client-com-spec=PokeIDCR_e_APM_FailureType, required-interface=PokeIDCR_e_APM_FailureType
      FsftIDCR_I_APM_HV_Current: client-com-spec=FsftIDCR_I_APM_HV_Current, required-interface=FsftIDCR_I_APM_HV_Current
      PokeIDCR_I_APM_HV_Current: client-com-spec=PokeIDCR_I_APM_HV_Current, required-interface=PokeIDCR_I_APM_HV_Current
      FsftIDCR_U_APM_HV_Voltage: client-com-spec=FsftIDCR_U_APM_HV_Voltage, required-interface=FsftIDCR_U_APM_HV_Voltage
      PokeIDCR_U_APM_HV_Voltage: client-com-spec=PokeIDCR_U_APM_HV_Voltage, required-interface=PokeIDCR_U_APM_HV_Voltage
      PokeIDCR_b_HvOverVStatus: client-com-spec=PokeIDCR_b_HvOverVStatus, required-interface=PokeIDCR_b_HvOverVStatus
      FsftIDCR_U_APM_HvVsetPFdbk: client-com-spec=FsftIDCR_U_APM_HvVsetPFdbk, required-interface=FsftIDCR_U_APM_HvVsetPFdbk
      PokeIDCR_U_APM_HvVsetPFdbk: client-com-spec=PokeIDCR_U_APM_HvVsetPFdbk, required-interface=PokeIDCR_U_APM_HvVsetPFdbk
      FsftIDCR_I_IdcHvSetPFdbk: client-com-spec=FsftIDCR_I_IdcHvSetPFdbk, required-interface=FsftIDCR_I_IdcHvSetPFdbk
      PokeIDCR_I_IdcHvSetPFdbk: client-com-spec=PokeIDCR_I_IdcHvSetPFdbk, required-interface=PokeIDCR_I_IdcHvSetPFdbk
      FsftIDCR_P_APM_InputPower: client-com-spec=FsftIDCR_P_APM_InputPower, required-interface=FsftIDCR_P_APM_InputPower
      PokeIDCR_P_APM_InputPower: client-com-spec=PokeIDCR_P_APM_InputPower, required-interface=PokeIDCR_P_APM_InputPower
      FsftIDCR_I_APM_LV_Current: client-com-spec=FsftIDCR_I_APM_LV_Current, required-interface=FsftIDCR_I_APM_LV_Current
      PokeIDCR_I_APM_LV_Current: client-com-spec=PokeIDCR_I_APM_LV_Current, required-interface=PokeIDCR_I_APM_LV_Current
      FsftIDCR_U_APM_LV_Voltage: client-com-spec=FsftIDCR_U_APM_LV_Voltage, required-interface=FsftIDCR_U_APM_LV_Voltage
      PokeIDCR_U_APM_LV_Voltage: client-com-spec=PokeIDCR_U_APM_LV_Voltage, required-interface=PokeIDCR_U_APM_LV_Voltage
      FsftIDCR_P_APM_OutputPower: client-com-spec=FsftIDCR_P_APM_OutputPower, required-interface=FsftIDCR_P_APM_OutputPower
      PokeIDCR_P_APM_OutputPower: client-com-spec=PokeIDCR_P_APM_OutputPower, required-interface=PokeIDCR_P_APM_OutputPower
      FsftIDCR_T_Temp1: client-com-spec=FsftIDCR_T_Temp1, required-interface=FsftIDCR_T_Temp1
      PokeIDCR_T_Temp1: client-com-spec=PokeIDCR_T_Temp1, required-interface=PokeIDCR_T_Temp1
      FsftIDCR_T_Temp2: client-com-spec=FsftIDCR_T_Temp2, required-interface=FsftIDCR_T_Temp2
      PokeIDCR_T_Temp2: client-com-spec=PokeIDCR_T_Temp2, required-interface=PokeIDCR_T_Temp2
      PokeIDCR_b_HvTooLowVStatus: client-com-spec=PokeIDCR_b_HvTooLowVStatus, required-interface=PokeIDCR_b_HvTooLowVStatus
      FsftIDCR_T_APM_TempColdPlate: client-com-spec=FsftIDCR_T_APM_TempColdPlate, required-interface=FsftIDCR_T_APM_TempColdPlate
      PokeIDCR_T_APM_TempColdPlate: client-com-spec=PokeIDCR_T_APM_TempColdPlate, required-interface=PokeIDCR_T_APM_TempColdPlate
      PokeIDCR_e_APM_ThermalRunaway: client-com-spec=PokeIDCR_e_APM_ThermalRunaway, required-interface=PokeIDCR_e_APM_ThermalRunaway
      FsftIDCR_Pct_UtilPctOfDCDC: client-com-spec=FsftIDCR_Pct_UtilPctOfDCDC, required-interface=FsftIDCR_Pct_UtilPctOfDCDC
      PokeIDCR_Pct_UtilPctOfDCDC: client-com-spec=PokeIDCR_Pct_UtilPctOfDCDC, required-interface=PokeIDCR_Pct_UtilPctOfDCDC
      FsftIMPR_b_ImpactHardwire: client-com-spec=FsftIMPR_b_ImpactHardwire, required-interface=FsftIMPR_b_ImpactHardwire
      PokeIMPR_b_ImpactHardwire: client-com-spec=PokeIMPR_b_ImpactHardwire, required-interface=PokeIMPR_b_ImpactHardwire
      FsftIMPR_b_ImpactHardwireV: client-com-spec=FsftIMPR_b_ImpactHardwireV, required-interface=FsftIMPR_b_ImpactHardwireV
      PokeIMPR_b_ImpactHardwireV: client-com-spec=PokeIMPR_b_ImpactHardwireV, required-interface=PokeIMPR_b_ImpactHardwireV
      FsftTMIR_T_HV_BatHghTmp_Thrsh: client-com-spec=FsftTMIR_T_HV_BatHghTmp_Thrsh, required-interface=FsftTMIR_T_HV_BatHghTmp_Thrsh
      PokeTMIR_T_HV_BatHghTmp_Thrsh: client-com-spec=PokeTMIR_T_HV_BatHghTmp_Thrsh, required-interface=PokeTMIR_T_HV_BatHghTmp_Thrsh
      FsftTMIR_T_HV_BatLowTmp_Thrsh: client-com-spec=FsftTMIR_T_HV_BatLowTmp_Thrsh, required-interface=FsftTMIR_T_HV_BatLowTmp_Thrsh
      PokeTMIR_T_HV_BatLowTmp_Thrsh: client-com-spec=PokeTMIR_T_HV_BatLowTmp_Thrsh, required-interface=PokeTMIR_T_HV_BatLowTmp_Thrsh
      PokeBPCR_b_HEVOnRqBPCM: client-com-spec=PokeBPCR_b_HEVOnRqBPCM, required-interface=PokeBPCR_b_HEVOnRqBPCM
      FsftBPCR_U_CellVoltHighThrsh: client-com-spec=FsftBPCR_U_CellVoltHighThrsh, required-interface=FsftBPCR_U_CellVoltHighThrsh
      PokeBPCR_U_CellVoltHighThrsh: client-com-spec=PokeBPCR_U_CellVoltHighThrsh, required-interface=PokeBPCR_U_CellVoltHighThrsh
      FsftBPCR_U_CellVoltLowThrsh: client-com-spec=FsftBPCR_U_CellVoltLowThrsh, required-interface=FsftBPCR_U_CellVoltLowThrsh
      PokeBPCR_U_CellVoltLowThrsh: client-com-spec=PokeBPCR_U_CellVoltLowThrsh, required-interface=PokeBPCR_U_CellVoltLowThrsh
      PokeBPCR_b_HV_BatCntctrOpenPending: client-com-spec=PokeBPCR_b_HV_BatCntctrOpenPending, required-interface=PokeBPCR_b_HV_BatCntctrOpenPending
      PokeBPCR_b_HV_BatCntctrOpenReq: client-com-spec=PokeBPCR_b_HV_BatCntctrOpenReq, required-interface=PokeBPCR_b_HV_BatCntctrOpenReq
      FsftBPCR_Z_MaxCellDischargeImpedance: client-com-spec=FsftBPCR_Z_MaxCellDischargeImpedance, required-interface=FsftBPCR_Z_MaxCellDischargeImpedance
      PokeBPCR_Z_MaxCellDischargeImpedance: client-com-spec=PokeBPCR_Z_MaxCellDischargeImpedance, required-interface=PokeBPCR_Z_MaxCellDischargeImpedance
      FsftBPCR_Z_MinCellDischargeImpedance: client-com-spec=FsftBPCR_Z_MinCellDischargeImpedance, required-interface=FsftBPCR_Z_MinCellDischargeImpedance
      PokeBPCR_Z_MinCellDischargeImpedance: client-com-spec=PokeBPCR_Z_MinCellDischargeImpedance, required-interface=PokeBPCR_Z_MinCellDischargeImpedance
      FsftBPCR_I_MaxChgCurrAlwd: client-com-spec=FsftBPCR_I_MaxChgCurrAlwd, required-interface=FsftBPCR_I_MaxChgCurrAlwd
      PokeBPCR_I_MaxChgCurrAlwd: client-com-spec=PokeBPCR_I_MaxChgCurrAlwd, required-interface=PokeBPCR_I_MaxChgCurrAlwd
      FsftBPCR_e_ChargingStat_BPCM: client-com-spec=FsftBPCR_e_ChargingStat_BPCM, required-interface=FsftBPCR_e_ChargingStat_BPCM
      PokeBPCR_e_ChargingStat_BPCM: client-com-spec=PokeBPCR_e_ChargingStat_BPCM, required-interface=PokeBPCR_e_ChargingStat_BPCM
      FsftBPCR_b_HV_BatChrgPwrET: client-com-spec=FsftBPCR_b_HV_BatChrgPwrET, required-interface=FsftBPCR_b_HV_BatChrgPwrET
      PokeBPCR_P_HV_BatChrgPwrET: client-com-spec=PokeBPCR_P_HV_BatChrgPwrET, required-interface=PokeBPCR_P_HV_BatChrgPwrET
      TmotBPCR_b_HV_BatChrgPwrET: client-com-spec=TmotBPCR_b_HV_BatChrgPwrET, required-interface=TmotBPCR_b_HV_BatChrgPwrET
      FsftBPCR_b_HV_BatChrgPwrLT: client-com-spec=FsftBPCR_b_HV_BatChrgPwrLT, required-interface=FsftBPCR_b_HV_BatChrgPwrLT
      PokeBPCR_P_HV_BatChrgPwrLT: client-com-spec=PokeBPCR_P_HV_BatChrgPwrLT, required-interface=PokeBPCR_P_HV_BatChrgPwrLT
      TmotBPCR_b_HV_BatChrgPwrLT: client-com-spec=TmotBPCR_b_HV_BatChrgPwrLT, required-interface=TmotBPCR_b_HV_BatChrgPwrLT
      FsftBPCR_b_HV_BatChrgPwrST: client-com-spec=FsftBPCR_b_HV_BatChrgPwrST, required-interface=FsftBPCR_b_HV_BatChrgPwrST
      PokeBPCR_P_HV_BatChrgPwrST: client-com-spec=PokeBPCR_P_HV_BatChrgPwrST, required-interface=PokeBPCR_P_HV_BatChrgPwrST
      TmotBPCR_b_HV_BatChrgPwrST: client-com-spec=TmotBPCR_b_HV_BatChrgPwrST, required-interface=TmotBPCR_b_HV_BatChrgPwrST
      FsftBPCR_b_HV_BatDschrgPwrET: client-com-spec=FsftBPCR_b_HV_BatDschrgPwrET, required-interface=FsftBPCR_b_HV_BatDschrgPwrET
      PokeBPCR_P_HV_BatDschrgPwrET: client-com-spec=PokeBPCR_P_HV_BatDschrgPwrET, required-interface=PokeBPCR_P_HV_BatDschrgPwrET
      TmotBPCR_b_HV_BatDschrgPwrET: client-com-spec=TmotBPCR_b_HV_BatDschrgPwrET, required-interface=TmotBPCR_b_HV_BatDschrgPwrET
      FsftBPCR_b_HV_BatDschrgPwrLT: client-com-spec=FsftBPCR_b_HV_BatDschrgPwrLT, required-interface=FsftBPCR_b_HV_BatDschrgPwrLT
      PokeBPCR_P_HV_BatDschrgPwrLT: client-com-spec=PokeBPCR_P_HV_BatDschrgPwrLT, required-interface=PokeBPCR_P_HV_BatDschrgPwrLT
      TmotBPCR_b_HV_BatDschrgPwrLT: client-com-spec=TmotBPCR_b_HV_BatDschrgPwrLT, required-interface=TmotBPCR_b_HV_BatDschrgPwrLT
      FsftBPCR_b_HV_BatDschrgPwrST: client-com-spec=FsftBPCR_b_HV_BatDschrgPwrST, required-interface=FsftBPCR_b_HV_BatDschrgPwrST
      PokeBPCR_P_HV_BatDschrgPwrST: client-com-spec=PokeBPCR_P_HV_BatDschrgPwrST, required-interface=PokeBPCR_P_HV_BatDschrgPwrST
      TmotBPCR_b_HV_BatDschrgPwrST: client-com-spec=TmotBPCR_b_HV_BatDschrgPwrST, required-interface=TmotBPCR_b_HV_BatDschrgPwrST
      FsftBPCR_e_HV_BatInrlkStat: client-com-spec=FsftBPCR_e_HV_BatInrlkStat, required-interface=FsftBPCR_e_HV_BatInrlkStat
      PokeBPCR_e_HV_BatInrlkStat: client-com-spec=PokeBPCR_e_HV_BatInrlkStat, required-interface=PokeBPCR_e_HV_BatInrlkStat
      PokeBPCR_b_HVBat_DC_CntctrReq: client-com-spec=PokeBPCR_b_HVBat_DC_CntctrReq, required-interface=PokeBPCR_b_HVBat_DC_CntctrReq
      PokeBPCR_b_HVBat_DC_CntctrOpn: client-com-spec=PokeBPCR_b_HVBat_DC_CntctrOpn, required-interface=PokeBPCR_b_HVBat_DC_CntctrOpn
      PokeBPCR_b_BalMd: client-com-spec=PokeBPCR_b_BalMd, required-interface=PokeBPCR_b_BalMd
      FsftBPCR_e_HVBatIntrlkIntrnlStat: client-com-spec=FsftBPCR_e_HVBatIntrlkIntrnlStat, required-interface=FsftBPCR_e_HVBatIntrlkIntrnlStat
      PokeBPCR_e_HVBatIntrlkIntrnlStat: client-com-spec=PokeBPCR_e_HVBatIntrlkIntrnlStat, required-interface=PokeBPCR_e_HVBatIntrlkIntrnlStat
      FsftBPCR_e_HV_BatIsolStat: client-com-spec=FsftBPCR_e_HV_BatIsolStat, required-interface=FsftBPCR_e_HV_BatIsolStat
      PokeBPCR_e_HV_BatIsolStat: client-com-spec=PokeBPCR_e_HV_BatIsolStat, required-interface=PokeBPCR_e_HV_BatIsolStat
      PokeBPCR_i_DC_Isolation_Sts_M182: client-com-spec=PokeBPCR_i_DC_Isolation_Sts_M182, required-interface=PokeBPCR_i_DC_Isolation_Sts_M182
      FsftBPCR_q_FullAmpHrCap: client-com-spec=FsftBPCR_q_FullAmpHrCap, required-interface=FsftBPCR_q_FullAmpHrCap
      PokeBPCR_q_FullAmpHrCap: client-com-spec=PokeBPCR_q_FullAmpHrCap, required-interface=PokeBPCR_q_FullAmpHrCap
      FsftBPCR_b_HVBat_DC_CntctrStat: client-com-spec=FsftBPCR_b_HVBat_DC_CntctrStat, required-interface=FsftBPCR_b_HVBat_DC_CntctrStat
      PokeBPCR_e_HVBat_DC_CntctrStat: client-com-spec=PokeBPCR_e_HVBat_DC_CntctrStat, required-interface=PokeBPCR_e_HVBat_DC_CntctrStat
      FsftBPCR_I_HV_BatCurr: client-com-spec=FsftBPCR_I_HV_BatCurr, required-interface=FsftBPCR_I_HV_BatCurr
      PokeBPCR_I_HV_BatCurr: client-com-spec=PokeBPCR_I_HV_BatCurr, required-interface=PokeBPCR_I_HV_BatCurr
      FsftBPCR_b_HV_BatCurrString2: client-com-spec=FsftBPCR_b_HV_BatCurrString2, required-interface=FsftBPCR_b_HV_BatCurrString2
      PokeBPCR_I_HV_BatCurrString2: client-com-spec=PokeBPCR_I_HV_BatCurrString2, required-interface=PokeBPCR_I_HV_BatCurrString2
      FsftBPCR_e_DCIsolSts: client-com-spec=FsftBPCR_e_DCIsolSts, required-interface=FsftBPCR_e_DCIsolSts
      PokeBPCR_e_DCIsolSts: client-com-spec=PokeBPCR_e_DCIsolSts, required-interface=PokeBPCR_e_DCIsolSts
      FsftTRIR_T_HV_BatClntTmp_In: client-com-spec=FsftTRIR_T_HV_BatClntTmp_In, required-interface=FsftTRIR_T_HV_BatClntTmp_In
      PokeTRIR_T_HV_BatClntTmp_In: client-com-spec=PokeTRIR_T_HV_BatClntTmp_In, required-interface=PokeTRIR_T_HV_BatClntTmp_In
      FsftBPCR_b_HV_InternalVolt: client-com-spec=FsftBPCR_b_HV_InternalVolt, required-interface=FsftBPCR_b_HV_InternalVolt
      PokeBPCR_U_HV_InternalVolt: client-com-spec=PokeBPCR_U_HV_InternalVolt, required-interface=PokeBPCR_U_HV_InternalVolt
      FsftBPCR_b_HV_InternalStringVolt1: client-com-spec=FsftBPCR_b_HV_InternalStringVolt1, required-interface=FsftBPCR_b_HV_InternalStringVolt1
      PokeBPCR_U_HV_InternalStringVolt1: client-com-spec=PokeBPCR_U_HV_InternalStringVolt1, required-interface=PokeBPCR_U_HV_InternalStringVolt1
      FsftBPCR_b_HV_InternalStringVolt2: client-com-spec=FsftBPCR_b_HV_InternalStringVolt2, required-interface=FsftBPCR_b_HV_InternalStringVolt2
      PokeBPCR_U_HV_InternalStringVolt2: client-com-spec=PokeBPCR_U_HV_InternalStringVolt2, required-interface=PokeBPCR_U_HV_InternalStringVolt2
      FsftTRIR_T_HV_BatClntTmpOut: client-com-spec=FsftTRIR_T_HV_BatClntTmpOut, required-interface=FsftTRIR_T_HV_BatClntTmpOut
      PokeTRIR_T_HV_BatClntTmp_Out: client-com-spec=PokeTRIR_T_HV_BatClntTmp_Out, required-interface=PokeTRIR_T_HV_BatClntTmp_Out
      FsftBPCR_b_HV_BatPackSOC: client-com-spec=FsftBPCR_b_HV_BatPackSOC, required-interface=FsftBPCR_b_HV_BatPackSOC
      PokeBPCR_Pct_HV_BatPackSOC: client-com-spec=PokeBPCR_Pct_HV_BatPackSOC, required-interface=PokeBPCR_Pct_HV_BatPackSOC
      TmotBPCR_b_HV_BatPackSOC: client-com-spec=TmotBPCR_b_HV_BatPackSOC, required-interface=TmotBPCR_b_HV_BatPackSOC
      PokeBPCR_Pct_HVBatSOH: client-com-spec=PokeBPCR_Pct_HVBatSOH, required-interface=PokeBPCR_Pct_HVBatSOH
      PokeBPCR_Pct_HVBatSOHLow: client-com-spec=PokeBPCR_Pct_HVBatSOHLow, required-interface=PokeBPCR_Pct_HVBatSOHLow
      FsftBPCR_b_HV_BatModTempAvg: client-com-spec=FsftBPCR_b_HV_BatModTempAvg, required-interface=FsftBPCR_b_HV_BatModTempAvg
      PokeBPCR_T_HV_BatModTempAvg: client-com-spec=PokeBPCR_T_HV_BatModTempAvg, required-interface=PokeBPCR_T_HV_BatModTempAvg
      TmotBPCR_b_HV_BatModTempAvg: client-com-spec=TmotBPCR_b_HV_BatModTempAvg, required-interface=TmotBPCR_b_HV_BatModTempAvg
      FsftBPCR_b_HV_BatModTempMax: client-com-spec=FsftBPCR_b_HV_BatModTempMax, required-interface=FsftBPCR_b_HV_BatModTempMax
      PokeBPCR_T_HV_BatModTempMax: client-com-spec=PokeBPCR_T_HV_BatModTempMax, required-interface=PokeBPCR_T_HV_BatModTempMax
      TmotBPCR_b_HV_BatModTempMax: client-com-spec=TmotBPCR_b_HV_BatModTempMax, required-interface=TmotBPCR_b_HV_BatModTempMax
      FsftBPCR_b_HV_BatModTempMin: client-com-spec=FsftBPCR_b_HV_BatModTempMin, required-interface=FsftBPCR_b_HV_BatModTempMin
      PokeBPCR_T_HV_BatModTempMin: client-com-spec=PokeBPCR_T_HV_BatModTempMin, required-interface=PokeBPCR_T_HV_BatModTempMin
      TmotBPCR_b_HV_BatModTempMin: client-com-spec=TmotBPCR_b_HV_BatModTempMin, required-interface=TmotBPCR_b_HV_BatModTempMin
      FsftBPCR_b_ThrmlRnawy_Warn: client-com-spec=FsftBPCR_b_ThrmlRnawy_Warn, required-interface=FsftBPCR_b_ThrmlRnawy_Warn
      PokeBPCR_e_ThrmlRnawy_Warn: client-com-spec=PokeBPCR_e_ThrmlRnawy_Warn, required-interface=PokeBPCR_e_ThrmlRnawy_Warn
      FsftBPCR_e_HV_BatCntctrStat: client-com-spec=FsftBPCR_e_HV_BatCntctrStat, required-interface=FsftBPCR_e_HV_BatCntctrStat
      PokeBPCR_e_HV_BatCntctrStat: client-com-spec=PokeBPCR_e_HV_BatCntctrStat, required-interface=PokeBPCR_e_HV_BatCntctrStat
      FsftBPCR_b_HV_TracBatCntctrConfig: variation-point={short-label=vpFsftBPCR_b_HV_TracBatCntctrConfig, sw-syscond=1}, client-com-spec=FsftBPCR_b_HV_TracBatCntctrConfig, required-interface=FsftBPCR_b_HV_TracBatCntctrConfig
      PokeBPCR_e_HV_TracBatCntctrConfig: variation-point={short-label=vpPokeBPCR_e_HV_TracBatCntctrConfig, sw-syscond=1}, client-com-spec=PokeBPCR_e_HV_TracBatCntctrConfig, required-interface=PokeBPCR_e_HV_TracBatCntctrConfig
      FsftBPCR_b_HVBatCntrWeld_ImpdOpn: client-com-spec=FsftBPCR_b_HVBatCntrWeld_ImpdOpn, required-interface=FsftBPCR_b_HVBatCntrWeld_ImpdOpn
      PokeBPCR_e_HVBatCntrWeld_ImpdOpn: client-com-spec=PokeBPCR_e_HVBatCntrWeld_ImpdOpn, required-interface=PokeBPCR_e_HVBatCntrWeld_ImpdOpn
      TmotBPCR_b_HVBatCntrWeld_ImpdOpn: client-com-spec=TmotBPCR_b_HVBatCntrWeld_ImpdOpn, required-interface=TmotBPCR_b_HVBatCntrWeld_ImpdOpn
      FsftBPCR_U_HV_BatVolt: client-com-spec=FsftBPCR_U_HV_BatVolt, required-interface=FsftBPCR_U_HV_BatVolt
      PokeBPCR_U_HV_BatVolt: client-com-spec=PokeBPCR_U_HV_BatVolt, required-interface=PokeBPCR_U_HV_BatVolt
      PokeBPCR_b_PwrLimON: client-com-spec=PokeBPCR_b_PwrLimON, required-interface=PokeBPCR_b_PwrLimON
      FsftBPCR_b_HV_AuxLoadOffReq: variation-point={short-label=vpFsftBPCR_b_HV_AuxLoadOffReq, sw-syscond=1}, client-com-spec=FsftBPCR_b_HV_AuxLoadOffReq, required-interface=FsftBPCR_b_HV_AuxLoadOffReq
      PokeBPCR_b_HV_AuxLoadOffReq: variation-point={short-label=vpPokeBPCR_b_HV_AuxLoadOffReq, sw-syscond=1}, client-com-spec=PokeBPCR_b_HV_AuxLoadOffReq, required-interface=PokeBPCR_b_HV_AuxLoadOffReq
      FsftBPCR_b_HV_SeriesVolt: variation-point={short-label=vpFsftBPCR_b_HV_SeriesVolt, sw-syscond=1}, client-com-spec=FsftBPCR_b_HV_SeriesVolt, required-interface=FsftBPCR_b_HV_SeriesVolt
      PokeBPCR_U_HV_SeriesVolt: variation-point={short-label=vpPokeBPCR_U_HV_SeriesVolt, sw-syscond=1}, client-com-spec=PokeBPCR_U_HV_SeriesVolt, required-interface=PokeBPCR_U_HV_SeriesVolt
      FsftBPCR_b_HV_DcChargeTypeStat: variation-point={short-label=vpFsftBPCR_b_HV_DcChargeTypeStat, sw-syscond=1}, client-com-spec=FsftBPCR_b_HV_DcChargeTypeStat, required-interface=FsftBPCR_b_HV_DcChargeTypeStat
      PokeBPCR_e_HV_DcChargeTypeStat: variation-point={short-label=vpPokeBPCR_e_HV_DcChargeTypeStat, sw-syscond=1}, client-com-spec=PokeBPCR_e_HV_DcChargeTypeStat, required-interface=PokeBPCR_e_HV_DcChargeTypeStat
      PokeBPCR_T_BDUBusBarTemp: client-com-spec=PokeBPCR_T_BDUBusBarTemp, required-interface=PokeBPCR_T_BDUBusBarTemp
      PokeBPCR_T_BusBarTemp: client-com-spec=PokeBPCR_T_BusBarTemp, required-interface=PokeBPCR_T_BusBarTemp
      FsftBPCR_t_HVBattCntctrOpnTm: client-com-spec=FsftBPCR_t_HVBattCntctrOpnTm, required-interface=FsftBPCR_t_HVBattCntctrOpnTm
      PokeBPCR_t_HVBattCntctrOpnTm: client-com-spec=PokeBPCR_t_HVBattCntctrOpnTm, required-interface=PokeBPCR_t_HVBattCntctrOpnTm
      PokeBPCR_b_StkOpnChkCmpl: client-com-spec=PokeBPCR_b_StkOpnChkCmpl, required-interface=PokeBPCR_b_StkOpnChkCmpl
      PokeBPCR_t_HVBatSleepTime: client-com-spec=PokeBPCR_t_HVBatSleepTime, required-interface=PokeBPCR_t_HVBatSleepTime
      FsftBPCR_b_HVBatRdy: client-com-spec=FsftBPCR_b_HVBatRdy, required-interface=FsftBPCR_b_HVBatRdy
      PokeBPCR_b_HVBatRdy: client-com-spec=PokeBPCR_b_HVBatRdy, required-interface=PokeBPCR_b_HVBatRdy
      FsftBPCR_U_HV_BatModVoltAvg: client-com-spec=FsftBPCR_U_HV_BatModVoltAvg, required-interface=FsftBPCR_U_HV_BatModVoltAvg
      PokeBPCR_U_HV_BatModVoltAvg: client-com-spec=PokeBPCR_U_HV_BatModVoltAvg, required-interface=PokeBPCR_U_HV_BatModVoltAvg
      FsftBPCR_U_HV_BatModVoltMax: client-com-spec=FsftBPCR_U_HV_BatModVoltMax, required-interface=FsftBPCR_U_HV_BatModVoltMax
      PokeBPCR_U_HV_BatModVoltMax: client-com-spec=PokeBPCR_U_HV_BatModVoltMax, required-interface=PokeBPCR_U_HV_BatModVoltMax
      FsftBPCR_U_HV_BatModVoltMin: client-com-spec=FsftBPCR_U_HV_BatModVoltMin, required-interface=FsftBPCR_U_HV_BatModVoltMin
      PokeBPCR_U_HV_BatModVoltMin: client-com-spec=PokeBPCR_U_HV_BatModVoltMin, required-interface=PokeBPCR_U_HV_BatModVoltMin
      PokeBPCR_cnt_HVBatt_ModNumMaxTmp: client-com-spec=PokeBPCR_cnt_HVBatt_ModNumMaxTmp, required-interface=PokeBPCR_cnt_HVBatt_ModNumMaxTmp
      PokeBPCR_Cnt_HVBatt_NumMaxVlt: client-com-spec=PokeBPCR_Cnt_HVBatt_NumMaxVlt, required-interface=PokeBPCR_Cnt_HVBatt_NumMaxVlt
      PokeBPCR_cnt_HVBatt_ModNumMinTmp: client-com-spec=PokeBPCR_cnt_HVBatt_ModNumMinTmp, required-interface=PokeBPCR_cnt_HVBatt_ModNumMinTmp
      PokeBPCR_Cnt_HVBatt_NumMinVlt: client-com-spec=PokeBPCR_Cnt_HVBatt_NumMinVlt, required-interface=PokeBPCR_Cnt_HVBatt_NumMinVlt
      FsftBPCR_U_MaxCellVltAlld: client-com-spec=FsftBPCR_U_MaxCellVltAlld, required-interface=FsftBPCR_U_MaxCellVltAlld
      PokeBPCR_U_MaxCellVltAlld: client-com-spec=PokeBPCR_U_MaxCellVltAlld, required-interface=PokeBPCR_U_MaxCellVltAlld
      FsftBPCR_U_MaxPkVltAlld: client-com-spec=FsftBPCR_U_MaxPkVltAlld, required-interface=FsftBPCR_U_MaxPkVltAlld
      PokeBPCR_U_MaxPkVltAlld: client-com-spec=PokeBPCR_U_MaxPkVltAlld, required-interface=PokeBPCR_U_MaxPkVltAlld
      FsftBPCR_U_MinCellVltAlld: client-com-spec=FsftBPCR_U_MinCellVltAlld, required-interface=FsftBPCR_U_MinCellVltAlld
      PokeBPCR_U_MinCellVltAlld: client-com-spec=PokeBPCR_U_MinCellVltAlld, required-interface=PokeBPCR_U_MinCellVltAlld
      FsftBPCR_U_MinPkVltAlld: client-com-spec=FsftBPCR_U_MinPkVltAlld, required-interface=FsftBPCR_U_MinPkVltAlld
      PokeBPCR_U_MinPkVltAlld: client-com-spec=PokeBPCR_U_MinPkVltAlld, required-interface=PokeBPCR_U_MinPkVltAlld
      FsftBPCR_U_OCVAveCellVoltage: client-com-spec=FsftBPCR_U_OCVAveCellVoltage, required-interface=FsftBPCR_U_OCVAveCellVoltage
      PokeBPCR_U_OCVAveCellVoltage: client-com-spec=PokeBPCR_U_OCVAveCellVoltage, required-interface=PokeBPCR_U_OCVAveCellVoltage
      FsftBPCR_U_OCVMaxCellVoltage: client-com-spec=FsftBPCR_U_OCVMaxCellVoltage, required-interface=FsftBPCR_U_OCVMaxCellVoltage
      PokeBPCR_U_OCVMaxCellVoltage: client-com-spec=PokeBPCR_U_OCVMaxCellVoltage, required-interface=PokeBPCR_U_OCVMaxCellVoltage
      FsftBPCR_U_OCVMinCellVoltage: client-com-spec=FsftBPCR_U_OCVMinCellVoltage, required-interface=FsftBPCR_U_OCVMinCellVoltage
      PokeBPCR_U_OCVMinCellVoltage: client-com-spec=PokeBPCR_U_OCVMinCellVoltage, required-interface=PokeBPCR_U_OCVMinCellVoltage
      FsftTMIR_T_OBCMTemp1: client-com-spec=FsftTMIR_T_OBCMTemp1, required-interface=FsftTMIR_T_OBCMTemp1
      PokeTMIR_T_OBCMTemp1: client-com-spec=PokeTMIR_T_OBCMTemp1, required-interface=PokeTMIR_T_OBCMTemp1
      TmotTMIR_b_OBCMTemp1: client-com-spec=TmotTMIR_b_OBCMTemp1, required-interface=TmotTMIR_b_OBCMTemp1
      FsftTMIR_T_OBCMTemp2: client-com-spec=FsftTMIR_T_OBCMTemp2, required-interface=FsftTMIR_T_OBCMTemp2
      PokeTMIR_T_OBCMTemp2: client-com-spec=PokeTMIR_T_OBCMTemp2, required-interface=PokeTMIR_T_OBCMTemp2
      TmotTMIR_b_OBCMTemp2: client-com-spec=TmotTMIR_b_OBCMTemp2, required-interface=TmotTMIR_b_OBCMTemp2
      FsftTMIR_T_OBCMTemp3: client-com-spec=FsftTMIR_T_OBCMTemp3, required-interface=FsftTMIR_T_OBCMTemp3
      PokeTMIR_T_OBCMTemp3: client-com-spec=PokeTMIR_T_OBCMTemp3, required-interface=PokeTMIR_T_OBCMTemp3
      FsftTMIR_T_OBCMTemp4: client-com-spec=FsftTMIR_T_OBCMTemp4, required-interface=FsftTMIR_T_OBCMTemp4
      PokeTMIR_T_OBCMTemp4: client-com-spec=PokeTMIR_T_OBCMTemp4, required-interface=PokeTMIR_T_OBCMTemp4
      PokeIDCR_b_AC_LnHi: client-com-spec=PokeIDCR_b_AC_LnHi, required-interface=PokeIDCR_b_AC_LnHi
      PokeIDCR_b_AC_LnLow: client-com-spec=PokeIDCR_b_AC_LnLow, required-interface=PokeIDCR_b_AC_LnLow
      PokeIDCR_b_StatusACPresent: client-com-spec=PokeIDCR_b_StatusACPresent, required-interface=PokeIDCR_b_StatusACPresent
      FsftIDCR_I_AC_Side_Curr: client-com-spec=FsftIDCR_I_AC_Side_Curr, required-interface=FsftIDCR_I_AC_Side_Curr
      PokeIDCR_I_AC_Side_Curr: client-com-spec=PokeIDCR_I_AC_Side_Curr, required-interface=PokeIDCR_I_AC_Side_Curr
      FsftIDCR_I_ACSideCurr_L2: client-com-spec=FsftIDCR_I_ACSideCurr_L2, required-interface=FsftIDCR_I_ACSideCurr_L2
      PokeIDCR_I_ACSideCurr_L2: client-com-spec=PokeIDCR_I_ACSideCurr_L2, required-interface=PokeIDCR_I_ACSideCurr_L2
      FsftIDCR_I_ACSideCurr_L3: client-com-spec=FsftIDCR_I_ACSideCurr_L3, required-interface=FsftIDCR_I_ACSideCurr_L3
      PokeIDCR_I_ACSideCurr_L3: client-com-spec=PokeIDCR_I_ACSideCurr_L3, required-interface=PokeIDCR_I_ACSideCurr_L3
      FsftIDCR_U_AC_InputVltOBCM: client-com-spec=FsftIDCR_U_AC_InputVltOBCM, required-interface=FsftIDCR_U_AC_InputVltOBCM
      PokeIDCR_U_AC_InputVltOBCM: client-com-spec=PokeIDCR_U_AC_InputVltOBCM, required-interface=PokeIDCR_U_AC_InputVltOBCM
      FsftIDCR_U_ACSideVolt_L2: client-com-spec=FsftIDCR_U_ACSideVolt_L2, required-interface=FsftIDCR_U_ACSideVolt_L2
      PokeIDCR_U_ACSideVolt_L2: client-com-spec=PokeIDCR_U_ACSideVolt_L2, required-interface=PokeIDCR_U_ACSideVolt_L2
      FsftIDCR_U_ACSideVolt_L3: client-com-spec=FsftIDCR_U_ACSideVolt_L3, required-interface=FsftIDCR_U_ACSideVolt_L3
      PokeIDCR_U_ACSideVolt_L3: client-com-spec=PokeIDCR_U_ACSideVolt_L3, required-interface=PokeIDCR_U_ACSideVolt_L3
      FsftIDCR_I_BattSide_Curr: client-com-spec=FsftIDCR_I_BattSide_Curr, required-interface=FsftIDCR_I_BattSide_Curr
      PokeIDCR_I_BattSide_Curr: client-com-spec=PokeIDCR_I_BattSide_Curr, required-interface=PokeIDCR_I_BattSide_Curr
      FsftIDCR_U_BattSideVolt: client-com-spec=FsftIDCR_U_BattSideVolt, required-interface=FsftIDCR_U_BattSideVolt
      PokeIDCR_U_BattSideVolt: client-com-spec=PokeIDCR_U_BattSideVolt, required-interface=PokeIDCR_U_BattSideVolt
      FsftIDCR_I_ChrgCurrent: client-com-spec=FsftIDCR_I_ChrgCurrent, required-interface=FsftIDCR_I_ChrgCurrent
      PokeIDCR_I_ChrgCurrent: client-com-spec=PokeIDCR_I_ChrgCurrent, required-interface=PokeIDCR_I_ChrgCurrent
      FsftIDCR_I_ChrgCrntAvail: client-com-spec=FsftIDCR_I_ChrgCrntAvail, required-interface=FsftIDCR_I_ChrgCrntAvail
      PokeIDCR_I_ChrgCrntAvail: client-com-spec=PokeIDCR_I_ChrgCrntAvail, required-interface=PokeIDCR_I_ChrgCrntAvail
      FsftIDCR_e_EVSE_PilotStat_OBCM: client-com-spec=FsftIDCR_e_EVSE_PilotStat_OBCM, required-interface=FsftIDCR_e_EVSE_PilotStat_OBCM
      PokeIDCR_e_EVSE_PilotStat_OBCM: client-com-spec=PokeIDCR_e_EVSE_PilotStat_OBCM, required-interface=PokeIDCR_e_EVSE_PilotStat_OBCM
      FsftIDCR_e_EVCC_FailureRsn: client-com-spec=FsftIDCR_e_EVCC_FailureRsn, required-interface=FsftIDCR_e_EVCC_FailureRsn
      PokeIDCR_e_EVCC_FailureRsn: client-com-spec=PokeIDCR_e_EVCC_FailureRsn, required-interface=PokeIDCR_e_EVCC_FailureRsn
      FsftIDCR_I_J1772InputCrntAval: client-com-spec=FsftIDCR_I_J1772InputCrntAval, required-interface=FsftIDCR_I_J1772InputCrntAval
      PokeIDCR_I_J1772InputCrntAval: client-com-spec=PokeIDCR_I_J1772InputCrntAval, required-interface=PokeIDCR_I_J1772InputCrntAval
      FsftIDCR_b_J1772_S2_StatusFA: client-com-spec=FsftIDCR_b_J1772_S2_StatusFA, required-interface=FsftIDCR_b_J1772_S2_StatusFA
      PokeIDCR_b_J1772_S2_Status: client-com-spec=PokeIDCR_b_J1772_S2_Status, required-interface=PokeIDCR_b_J1772_S2_Status
      FsftIDCR_e_J1772Stat: client-com-spec=FsftIDCR_e_J1772Stat, required-interface=FsftIDCR_e_J1772Stat
      PokeIDCR_e_J1772Stat: client-com-spec=PokeIDCR_e_J1772Stat, required-interface=PokeIDCR_e_J1772Stat
      FsftIDCR_e_OBCM_HVILSts: client-com-spec=FsftIDCR_e_OBCM_HVILSts, required-interface=FsftIDCR_e_OBCM_HVILSts
      PokeIDCR_e_OBCM_HVILSts: client-com-spec=PokeIDCR_e_OBCM_HVILSts, required-interface=PokeIDCR_e_OBCM_HVILSts
      FsftIDCR_b_SDP_Sts: client-com-spec=FsftIDCR_b_SDP_Sts, required-interface=FsftIDCR_b_SDP_Sts
      PokeIDCR_e_SDP_Sts: client-com-spec=PokeIDCR_e_SDP_Sts, required-interface=PokeIDCR_e_SDP_Sts
      FsftIDCR_b_SLAC_Sts: client-com-spec=FsftIDCR_b_SLAC_Sts, required-interface=FsftIDCR_b_SLAC_Sts
      PokeIDCR_e_SLAC_Sts: client-com-spec=PokeIDCR_e_SLAC_Sts, required-interface=PokeIDCR_e_SLAC_Sts
      FsftIDCR_e_ProxStat: client-com-spec=FsftIDCR_e_ProxStat, required-interface=FsftIDCR_e_ProxStat
      PokeIDCR_e_ProxStat: client-com-spec=PokeIDCR_e_ProxStat, required-interface=PokeIDCR_e_ProxStat
      FsftIDCR_b_SupProtoNm: client-com-spec=FsftIDCR_b_SupProtoNm, required-interface=FsftIDCR_b_SupProtoNm
      PokeIDCR_e_SupProtoNm: client-com-spec=PokeIDCR_e_SupProtoNm, required-interface=PokeIDCR_e_SupProtoNm
      FsftIDCR_b_SupSchemaID: client-com-spec=FsftIDCR_b_SupSchemaID, required-interface=FsftIDCR_b_SupSchemaID
      PokeIDCR_e_SupSchemaID: client-com-spec=PokeIDCR_e_SupSchemaID, required-interface=PokeIDCR_e_SupSchemaID
      FsftIDCR_b_SupVerNumMajor: client-com-spec=FsftIDCR_b_SupVerNumMajor, required-interface=FsftIDCR_b_SupVerNumMajor
      PokeIDCR_e_SupVerNumMajor: client-com-spec=PokeIDCR_e_SupVerNumMajor, required-interface=PokeIDCR_e_SupVerNumMajor
      FsftIDCR_b_SupVerNumMinor: client-com-spec=FsftIDCR_b_SupVerNumMinor, required-interface=FsftIDCR_b_SupVerNumMinor
      PokeIDCR_e_SupVerNumMinor: client-com-spec=PokeIDCR_e_SupVerNumMinor, required-interface=PokeIDCR_e_SupVerNumMinor
      PokeIDCR_e_ChrgFailSts: client-com-spec=PokeIDCR_e_ChrgFailSts, required-interface=PokeIDCR_e_ChrgFailSts
      FsftIDCR_U_OBC_Prox: client-com-spec=FsftIDCR_U_OBC_Prox, required-interface=FsftIDCR_U_OBC_Prox
      PokeIDCR_U_OBC_Prox: client-com-spec=PokeIDCR_U_OBC_Prox, required-interface=PokeIDCR_U_OBC_Prox
      FsftIDCR_e_ChrgrModeStat_OBCM: client-com-spec=FsftIDCR_e_ChrgrModeStat_OBCM, required-interface=FsftIDCR_e_ChrgrModeStat_OBCM
      PokeIDCR_e_ChrgrModeStat_OBCM: client-com-spec=PokeIDCR_e_ChrgrModeStat_OBCM, required-interface=PokeIDCR_e_ChrgrModeStat_OBCM
      FsftIDCR_e_OBCM_Charger_Ready: client-com-spec=FsftIDCR_e_OBCM_Charger_Ready, required-interface=FsftIDCR_e_OBCM_Charger_Ready
      PokeIDCR_e_OBCM_Charger_Ready: client-com-spec=PokeIDCR_e_OBCM_Charger_Ready, required-interface=PokeIDCR_e_OBCM_Charger_Ready
      FsftIDCR_e_EVSE_CHAdeMOProtocol: client-com-spec=FsftIDCR_e_EVSE_CHAdeMOProtocol, required-interface=FsftIDCR_e_EVSE_CHAdeMOProtocol
      PokeIDCR_e_EVSE_CHAdeMOProtocol: client-com-spec=PokeIDCR_e_EVSE_CHAdeMOProtocol, required-interface=PokeIDCR_e_EVSE_CHAdeMOProtocol
      FsftIDCR_b_EVSE_ChargingSystemError: client-com-spec=FsftIDCR_b_EVSE_ChargingSystemError, required-interface=FsftIDCR_b_EVSE_ChargingSystemError
      PokeIDCR_b_EVSE_ChargingSystemError: client-com-spec=PokeIDCR_b_EVSE_ChargingSystemError, required-interface=PokeIDCR_b_EVSE_ChargingSystemError
      FsftIDCR_b_EVSE_EnergizingState: client-com-spec=FsftIDCR_b_EVSE_EnergizingState, required-interface=FsftIDCR_b_EVSE_EnergizingState
      PokeIDCR_b_EVSE_EnergizingState: client-com-spec=PokeIDCR_b_EVSE_EnergizingState, required-interface=PokeIDCR_b_EVSE_EnergizingState
      FsftIDCR_U_EVSE_ThrshldVoltage: client-com-spec=FsftIDCR_U_EVSE_ThrshldVoltage, required-interface=FsftIDCR_U_EVSE_ThrshldVoltage
      PokeIDCR_U_EVSE_ThrshldVoltage: client-com-spec=PokeIDCR_U_EVSE_ThrshldVoltage, required-interface=PokeIDCR_U_EVSE_ThrshldVoltage
      FsftIDCR_b_EVSE_Offered_AC_Single_Phase: client-com-spec=FsftIDCR_b_EVSE_Offered_AC_Single_Phase, required-interface=FsftIDCR_b_EVSE_Offered_AC_Single_Phase
      PokeIDCR_b_EVSE_Offered_AC_Single_Phase: client-com-spec=PokeIDCR_b_EVSE_Offered_AC_Single_Phase, required-interface=PokeIDCR_b_EVSE_Offered_AC_Single_Phase
      FsftIDCR_b_EVSE_Offered_AC_Three_Phase: client-com-spec=FsftIDCR_b_EVSE_Offered_AC_Three_Phase, required-interface=FsftIDCR_b_EVSE_Offered_AC_Three_Phase
      PokeIDCR_b_EVSE_Offered_AC_Three_Phase: client-com-spec=PokeIDCR_b_EVSE_Offered_AC_Three_Phase, required-interface=PokeIDCR_b_EVSE_Offered_AC_Three_Phase
      FsftIDCR_b_EVSE_Offered_DC_Extended: client-com-spec=FsftIDCR_b_EVSE_Offered_DC_Extended, required-interface=FsftIDCR_b_EVSE_Offered_DC_Extended
      PokeIDCR_b_EVSE_Offered_DC_Extended: client-com-spec=PokeIDCR_b_EVSE_Offered_DC_Extended, required-interface=PokeIDCR_b_EVSE_Offered_DC_Extended
      FsftIDCR_b_EVSE_Service1_Charging: client-com-spec=FsftIDCR_b_EVSE_Service1_Charging, required-interface=FsftIDCR_b_EVSE_Service1_Charging
      PokeIDCR_b_EVSE_Service1_Charging: client-com-spec=PokeIDCR_b_EVSE_Service1_Charging, required-interface=PokeIDCR_b_EVSE_Service1_Charging
      FsftIDCR_b_EVSE_Service1_Free: client-com-spec=FsftIDCR_b_EVSE_Service1_Free, required-interface=FsftIDCR_b_EVSE_Service1_Free
      PokeIDCR_b_EVSE_Service1_Free: client-com-spec=PokeIDCR_b_EVSE_Service1_Free, required-interface=PokeIDCR_b_EVSE_Service1_Free
      FsftIDCR_cmp_ISO15118_EVSETimeStamp: client-com-spec=FsftIDCR_cmp_ISO15118_EVSETimeStamp, required-interface=FsftIDCR_cmp_ISO15118_EVSETimeStamp
      PokeIDCR_cmp_ISO15118_EVSETimeStamp: client-com-spec=PokeIDCR_cmp_ISO15118_EVSETimeStamp, required-interface=PokeIDCR_cmp_ISO15118_EVSETimeStamp
      FsftIDCR_e_ISO15118_MessageResponse: client-com-spec=FsftIDCR_e_ISO15118_MessageResponse, required-interface=FsftIDCR_e_ISO15118_MessageResponse
      PokeIDCR_e_ISO15118_MessageResponse: client-com-spec=PokeIDCR_e_ISO15118_MessageResponse, required-interface=PokeIDCR_e_ISO15118_MessageResponse
      FsftIDCR_t_ISO15118_NotificationMaxDelay: client-com-spec=FsftIDCR_t_ISO15118_NotificationMaxDelay, required-interface=FsftIDCR_t_ISO15118_NotificationMaxDelay
      PokeIDCR_t_ISO15118_NotificationMaxDelay: client-com-spec=PokeIDCR_t_ISO15118_NotificationMaxDelay, required-interface=PokeIDCR_t_ISO15118_NotificationMaxDelay
      FsftIDCR_e_ISO15118_ResponseCode: client-com-spec=FsftIDCR_e_ISO15118_ResponseCode, required-interface=FsftIDCR_e_ISO15118_ResponseCode
      PokeIDCR_e_ISO15118_ResponseCode: client-com-spec=PokeIDCR_e_ISO15118_ResponseCode, required-interface=PokeIDCR_e_ISO15118_ResponseCode
      FsftIDCR_i_ISO15118_SAScheduleTupleID: client-com-spec=FsftIDCR_i_ISO15118_SAScheduleTupleID, required-interface=FsftIDCR_i_ISO15118_SAScheduleTupleID
      PokeIDCR_i_ISO15118_SAScheduleTupleID: client-com-spec=PokeIDCR_i_ISO15118_SAScheduleTupleID, required-interface=PokeIDCR_i_ISO15118_SAScheduleTupleID
      FsftIDCR_y_ISO15118_SchemaID: client-com-spec=FsftIDCR_y_ISO15118_SchemaID, required-interface=FsftIDCR_y_ISO15118_SchemaID
      PokeIDCR_y_ISO15118_SchemaID: client-com-spec=PokeIDCR_y_ISO15118_SchemaID, required-interface=PokeIDCR_y_ISO15118_SchemaID
      FsftIDCR_d_ISO15118_ServiceID: client-com-spec=FsftIDCR_d_ISO15118_ServiceID, required-interface=FsftIDCR_d_ISO15118_ServiceID
      PokeIDCR_d_ISO15118_ServiceID: client-com-spec=PokeIDCR_d_ISO15118_ServiceID, required-interface=PokeIDCR_d_ISO15118_ServiceID
      FsftIDCR_b_ISO15118_TLS_Offered: client-com-spec=FsftIDCR_b_ISO15118_TLS_Offered, required-interface=FsftIDCR_b_ISO15118_TLS_Offered
      PokeIDCR_b_ISO15118_TLS_Offered: client-com-spec=PokeIDCR_b_ISO15118_TLS_Offered, required-interface=PokeIDCR_b_ISO15118_TLS_Offered
      FsftIDCR_e_ISO15118_TLS_Status: client-com-spec=FsftIDCR_e_ISO15118_TLS_Status, required-interface=FsftIDCR_e_ISO15118_TLS_Status
      PokeIDCR_e_ISO15118_TLS_Status: client-com-spec=PokeIDCR_e_ISO15118_TLS_Status, required-interface=PokeIDCR_e_ISO15118_TLS_Status
      FsftIDCR_y_ISO15118_VersionNumMajor: client-com-spec=FsftIDCR_y_ISO15118_VersionNumMajor, required-interface=FsftIDCR_y_ISO15118_VersionNumMajor
      PokeIDCR_y_ISO15118_VersionNumMajor: client-com-spec=PokeIDCR_y_ISO15118_VersionNumMajor, required-interface=PokeIDCR_y_ISO15118_VersionNumMajor
      FsftIDCR_y_ISO15118_VersionNumMinor: client-com-spec=FsftIDCR_y_ISO15118_VersionNumMinor, required-interface=FsftIDCR_y_ISO15118_VersionNumMinor
      PokeIDCR_y_ISO15118_VersionNumMinor: client-com-spec=PokeIDCR_y_ISO15118_VersionNumMinor, required-interface=PokeIDCR_y_ISO15118_VersionNumMinor
      FsftIDCR_b_V2X_EVSE_Service_5_Free: client-com-spec=FsftIDCR_b_V2X_EVSE_Service_5_Free, required-interface=FsftIDCR_b_V2X_EVSE_Service_5_Free
      PokeIDCR_b_V2X_EVSE_Service_5_Free: client-com-spec=PokeIDCR_b_V2X_EVSE_Service_5_Free, required-interface=PokeIDCR_b_V2X_EVSE_Service_5_Free
      FsftIDCR_b_IDCM_Wakeup_HCP: client-com-spec=FsftIDCR_b_IDCM_Wakeup_HCP, required-interface=FsftIDCR_b_IDCM_Wakeup_HCP
      PokeIDCR_b_IDCM_Wakeup_HCP: client-com-spec=PokeIDCR_b_IDCM_Wakeup_HCP, required-interface=PokeIDCR_b_IDCM_Wakeup_HCP
      FsftIDCR_b_DC_Isolation_Disable_Cmd: client-com-spec=FsftIDCR_b_DC_Isolation_Disable_Cmd, required-interface=FsftIDCR_b_DC_Isolation_Disable_Cmd
      PokeIDCR_b_DC_Isolation_Disable_Cmd: client-com-spec=PokeIDCR_b_DC_Isolation_Disable_Cmd, required-interface=PokeIDCR_b_DC_Isolation_Disable_Cmd
      PokeIDCR_b_DC_TimeOut: client-com-spec=PokeIDCR_b_DC_TimeOut, required-interface=PokeIDCR_b_DC_TimeOut
      FsftIDCR_d_EVSE_Accepted_Protocol: client-com-spec=FsftIDCR_d_EVSE_Accepted_Protocol, required-interface=FsftIDCR_d_EVSE_Accepted_Protocol
      PokeIDCR_d_EVSE_Accepted_Protocol: client-com-spec=PokeIDCR_d_EVSE_Accepted_Protocol, required-interface=PokeIDCR_d_EVSE_Accepted_Protocol
      PokeIDCR_b_EVSE_FreeService: client-com-spec=PokeIDCR_b_EVSE_FreeService, required-interface=PokeIDCR_b_EVSE_FreeService
      FsftIDCR_b_EVSEIsolSts: client-com-spec=FsftIDCR_b_EVSEIsolSts, required-interface=FsftIDCR_b_EVSEIsolSts
      PokeIDCR_e_EVSEIsolSts: client-com-spec=PokeIDCR_e_EVSEIsolSts, required-interface=PokeIDCR_e_EVSEIsolSts
      FsftIDCR_e_EVSE_Notification: client-com-spec=FsftIDCR_e_EVSE_Notification, required-interface=FsftIDCR_e_EVSE_Notification
      PokeIDCR_e_EVSE_Notification: client-com-spec=PokeIDCR_e_EVSE_Notification, required-interface=PokeIDCR_e_EVSE_Notification
      FsftIDCR_b_OffrdEnrgyTxType: client-com-spec=FsftIDCR_b_OffrdEnrgyTxType, required-interface=FsftIDCR_b_OffrdEnrgyTxType
      PokeIDCR_e_OffrdEnrgyTxType: client-com-spec=PokeIDCR_e_OffrdEnrgyTxType, required-interface=PokeIDCR_e_OffrdEnrgyTxType
      PokeIDCR_b_EVSE_OfferedPaymentContract: client-com-spec=PokeIDCR_b_EVSE_OfferedPaymentContract, required-interface=PokeIDCR_b_EVSE_OfferedPaymentContract
      PokeIDCR_b_EVSE_OfferedPaymentEIM: client-com-spec=PokeIDCR_b_EVSE_OfferedPaymentEIM, required-interface=PokeIDCR_b_EVSE_OfferedPaymentEIM
      FsftIDCR_b_OffrdPayOptn: client-com-spec=FsftIDCR_b_OffrdPayOptn, required-interface=FsftIDCR_b_OffrdPayOptn
      PokeIDCR_e_OffrdPayOptn: client-com-spec=PokeIDCR_e_OffrdPayOptn, required-interface=PokeIDCR_e_OffrdPayOptn
      FsftIDCR_e_EVSE_OfferedService: client-com-spec=FsftIDCR_e_EVSE_OfferedService, required-interface=FsftIDCR_e_EVSE_OfferedService
      PokeIDCR_e_EVSE_OfferedService: client-com-spec=PokeIDCR_e_EVSE_OfferedService, required-interface=PokeIDCR_e_EVSE_OfferedService
      PokeIDCR_b_EVSE_Service2_Certificate: client-com-spec=PokeIDCR_b_EVSE_Service2_Certificate, required-interface=PokeIDCR_b_EVSE_Service2_Certificate
      PokeIDCR_K_Service_ID: client-com-spec=PokeIDCR_K_Service_ID, required-interface=PokeIDCR_K_Service_ID
      PokeIDCR_b_EVSE_Supported_DIN: client-com-spec=PokeIDCR_b_EVSE_Supported_DIN, required-interface=PokeIDCR_b_EVSE_Supported_DIN
      PokeIDCR_b_EVSE_Supported_ISO1: client-com-spec=PokeIDCR_b_EVSE_Supported_ISO1, required-interface=PokeIDCR_b_EVSE_Supported_ISO1
      FsftIDCR_I_EVSECurr_RegTol: client-com-spec=FsftIDCR_I_EVSECurr_RegTol, required-interface=FsftIDCR_I_EVSECurr_RegTol
      PokeIDCR_I_EVSECurr_RegTol: client-com-spec=PokeIDCR_I_EVSECurr_RegTol, required-interface=PokeIDCR_I_EVSECurr_RegTol
      PokeIDCR_b_EVSECurrLmtAchvd: client-com-spec=PokeIDCR_b_EVSECurrLmtAchvd, required-interface=PokeIDCR_b_EVSECurrLmtAchvd
      FsftIDCR_I_EVSEMaxCurrLmt: client-com-spec=FsftIDCR_I_EVSEMaxCurrLmt, required-interface=FsftIDCR_I_EVSEMaxCurrLmt
      PokeIDCR_I_EVSEMaxCurrLmt: client-com-spec=PokeIDCR_I_EVSEMaxCurrLmt, required-interface=PokeIDCR_I_EVSEMaxCurrLmt
      FsftIDCR_P_EVSEMaxPwrLmt: client-com-spec=FsftIDCR_P_EVSEMaxPwrLmt, required-interface=FsftIDCR_P_EVSEMaxPwrLmt
      PokeIDCR_P_EVSEMaxPwrLmt: client-com-spec=PokeIDCR_P_EVSEMaxPwrLmt, required-interface=PokeIDCR_P_EVSEMaxPwrLmt
      FsftIDCR_U_EVSEMaxVoltLmt: client-com-spec=FsftIDCR_U_EVSEMaxVoltLmt, required-interface=FsftIDCR_U_EVSEMaxVoltLmt
      PokeIDCR_U_EVSEMaxVoltLmt: client-com-spec=PokeIDCR_U_EVSEMaxVoltLmt, required-interface=PokeIDCR_U_EVSEMaxVoltLmt
      FsftIDCR_I_EVSEMinCurrLmt: client-com-spec=FsftIDCR_I_EVSEMinCurrLmt, required-interface=FsftIDCR_I_EVSEMinCurrLmt
      PokeIDCR_I_EVSEMinCurrLmt: client-com-spec=PokeIDCR_I_EVSEMinCurrLmt, required-interface=PokeIDCR_I_EVSEMinCurrLmt
      FsftIDCR_U_EVSEMinVoltLmt: client-com-spec=FsftIDCR_U_EVSEMinVoltLmt, required-interface=FsftIDCR_U_EVSEMinVoltLmt
      PokeIDCR_U_EVSEMinVoltLmt: client-com-spec=PokeIDCR_U_EVSEMinVoltLmt, required-interface=PokeIDCR_U_EVSEMinVoltLmt
      FsftIDCR_I_EVSEPeakCurrRip: client-com-spec=FsftIDCR_I_EVSEPeakCurrRip, required-interface=FsftIDCR_I_EVSEPeakCurrRip
      PokeIDCR_I_EVSEPeakCurrRip: client-com-spec=PokeIDCR_I_EVSEPeakCurrRip, required-interface=PokeIDCR_I_EVSEPeakCurrRip
      PokeIDCR_b_EVSEPwrLmtAchvd: client-com-spec=PokeIDCR_b_EVSEPwrLmtAchvd, required-interface=PokeIDCR_b_EVSEPwrLmtAchvd
      FsftIDCR_I_EVSEOutputCurr: client-com-spec=FsftIDCR_I_EVSEOutputCurr, required-interface=FsftIDCR_I_EVSEOutputCurr
      PokeIDCR_I_EVSEOutputCurr: client-com-spec=PokeIDCR_I_EVSEOutputCurr, required-interface=PokeIDCR_I_EVSEOutputCurr
      FsftIDCR_U_EVSEOutputVolt: client-com-spec=FsftIDCR_U_EVSEOutputVolt, required-interface=FsftIDCR_U_EVSEOutputVolt
      PokeIDCR_U_EVSEOutputVolt: client-com-spec=PokeIDCR_U_EVSEOutputVolt, required-interface=PokeIDCR_U_EVSEOutputVolt
      PokeIDCR_b_EVSEProcessing: client-com-spec=PokeIDCR_b_EVSEProcessing, required-interface=PokeIDCR_b_EVSEProcessing
      PokeIDCR_e_EVSEStsCode: client-com-spec=PokeIDCR_e_EVSEStsCode, required-interface=PokeIDCR_e_EVSEStsCode
      PokeIDCR_b_EVSEVoltLmtAchvd: client-com-spec=PokeIDCR_b_EVSEVoltLmtAchvd, required-interface=PokeIDCR_b_EVSEVoltLmtAchvd
      FsftIDCR_E_EVSE_EnrgyToBeDlvrd: client-com-spec=FsftIDCR_E_EVSE_EnrgyToBeDlvrd, required-interface=FsftIDCR_E_EVSE_EnrgyToBeDlvrd
      PokeIDCR_E_EVSE_EnrgyToBeDlvrd: client-com-spec=PokeIDCR_E_EVSE_EnrgyToBeDlvrd, required-interface=PokeIDCR_E_EVSE_EnrgyToBeDlvrd
      FsftIDCR_b_Resp_Code: client-com-spec=FsftIDCR_b_Resp_Code, required-interface=FsftIDCR_b_Resp_Code
      PokeIDCR_e_Resp_Code: client-com-spec=PokeIDCR_e_Resp_Code, required-interface=PokeIDCR_e_Resp_Code
      FsftIDCR_b_TxMessageRequest: client-com-spec=FsftIDCR_b_TxMessageRequest, required-interface=FsftIDCR_b_TxMessageRequest
      PokeIDCR_e_TxMessageRequest: client-com-spec=PokeIDCR_e_TxMessageRequest, required-interface=PokeIDCR_e_TxMessageRequest
      PokeIDCR_i_IDCM_DCCA_M182: client-com-spec=PokeIDCR_i_IDCM_DCCA_M182, required-interface=PokeIDCR_i_IDCM_DCCA_M182
      FsftIDCR_b_ReceiptRequired: client-com-spec=FsftIDCR_b_ReceiptRequired, required-interface=FsftIDCR_b_ReceiptRequired
      PokeIDCR_b_ReceiptRequired: client-com-spec=PokeIDCR_b_ReceiptRequired, required-interface=PokeIDCR_b_ReceiptRequired
      FsftIDCR_b_V2X_EVSE_Service_5_V2H: client-com-spec=FsftIDCR_b_V2X_EVSE_Service_5_V2H, required-interface=FsftIDCR_b_V2X_EVSE_Service_5_V2H
      PokeIDCR_b_V2X_EVSE_Service_5_V2H: client-com-spec=PokeIDCR_b_V2X_EVSE_Service_5_V2H, required-interface=PokeIDCR_b_V2X_EVSE_Service_5_V2H
      FsftIDCR_e_Chrgr_FaultStates: client-com-spec=FsftIDCR_e_Chrgr_FaultStates, required-interface=FsftIDCR_e_Chrgr_FaultStates
      PokeIDCR_e_Chrgr_FaultStates: client-com-spec=PokeIDCR_e_Chrgr_FaultStates, required-interface=PokeIDCR_e_Chrgr_FaultStates
      FsftIDCR_e_Charger_WeldingDetectAvail: client-com-spec=FsftIDCR_e_Charger_WeldingDetectAvail, required-interface=FsftIDCR_e_Charger_WeldingDetectAvail
      PokeIDCR_e_Charger_WeldingDetectAvail: client-com-spec=PokeIDCR_e_Charger_WeldingDetectAvail, required-interface=PokeIDCR_e_Charger_WeldingDetectAvail
      FsftIDCR_b_EVCC_FailureSts: client-com-spec=FsftIDCR_b_EVCC_FailureSts, required-interface=FsftIDCR_b_EVCC_FailureSts
      PokeIDCR_b_EVCC_FailureSts: client-com-spec=PokeIDCR_b_EVCC_FailureSts, required-interface=PokeIDCR_b_EVCC_FailureSts
      FsftIDCR_e_EVSE_ChrgStopControl: client-com-spec=FsftIDCR_e_EVSE_ChrgStopControl, required-interface=FsftIDCR_e_EVSE_ChrgStopControl
      PokeIDCR_e_EVSE_ChrgStopControl: client-com-spec=PokeIDCR_e_EVSE_ChrgStopControl, required-interface=PokeIDCR_e_EVSE_ChrgStopControl
      FsftIDCR_e_EVSE_Error: client-com-spec=FsftIDCR_e_EVSE_Error, required-interface=FsftIDCR_e_EVSE_Error
      PokeIDCR_e_EVSE_Error: client-com-spec=PokeIDCR_e_EVSE_Error, required-interface=PokeIDCR_e_EVSE_Error
      FsftIDCR_t_EVSE_NotificationMaxDelay: client-com-spec=FsftIDCR_t_EVSE_NotificationMaxDelay, required-interface=FsftIDCR_t_EVSE_NotificationMaxDelay
      PokeIDCR_t_EVSE_NotificationMaxDelay: client-com-spec=PokeIDCR_t_EVSE_NotificationMaxDelay, required-interface=PokeIDCR_t_EVSE_NotificationMaxDelay
      FsftIDCR_e_ExtChargerSts: client-com-spec=FsftIDCR_e_ExtChargerSts, required-interface=FsftIDCR_e_ExtChargerSts
      PokeIDCR_e_ExtChargerSts: client-com-spec=PokeIDCR_e_ExtChargerSts, required-interface=PokeIDCR_e_ExtChargerSts
      FsftIDCR_g_HVCMS_EVSEID: client-com-spec=FsftIDCR_g_HVCMS_EVSEID, required-interface=FsftIDCR_g_HVCMS_EVSEID
      PokeIDCR_g_HVCMS_EVSEID: client-com-spec=PokeIDCR_g_HVCMS_EVSEID, required-interface=PokeIDCR_g_HVCMS_EVSEID
      PokeIDCR_e_Prox_GBT: client-com-spec=PokeIDCR_e_Prox_GBT, required-interface=PokeIDCR_e_Prox_GBT
      FsftIDCR_e_OBCM_CP1Sts: client-com-spec=FsftIDCR_e_OBCM_CP1Sts, required-interface=FsftIDCR_e_OBCM_CP1Sts
      PokeIDCR_e_OBCM_CP1Sts: client-com-spec=PokeIDCR_e_OBCM_CP1Sts, required-interface=PokeIDCR_e_OBCM_CP1Sts
      FsftIDCR_e_OBCM_CP2Sts: client-com-spec=FsftIDCR_e_OBCM_CP2Sts, required-interface=FsftIDCR_e_OBCM_CP2Sts
      PokeIDCR_e_OBCM_CP2Sts: client-com-spec=PokeIDCR_e_OBCM_CP2Sts, required-interface=PokeIDCR_e_OBCM_CP2Sts
      FsftIDCR_e_OBCM_CP3Sts: client-com-spec=FsftIDCR_e_OBCM_CP3Sts, required-interface=FsftIDCR_e_OBCM_CP3Sts
      PokeIDCR_e_OBCM_CP3Sts: client-com-spec=PokeIDCR_e_OBCM_CP3Sts, required-interface=PokeIDCR_e_OBCM_CP3Sts
      FsftIDCR_e_OBCM_CSSts: client-com-spec=FsftIDCR_e_OBCM_CSSts, required-interface=FsftIDCR_e_OBCM_CSSts
      PokeIDCR_e_OBCM_CSSts: client-com-spec=PokeIDCR_e_OBCM_CSSts, required-interface=PokeIDCR_e_OBCM_CSSts
      FsftIDCR_b_OBCM_Timeout: client-com-spec=FsftIDCR_b_OBCM_Timeout, required-interface=FsftIDCR_b_OBCM_Timeout
      PokeIDCR_b_OBCM_Timeout: client-com-spec=PokeIDCR_b_OBCM_Timeout, required-interface=PokeIDCR_b_OBCM_Timeout
      PokeIDCR_b_TCPCommTerminated: client-com-spec=PokeIDCR_b_TCPCommTerminated, required-interface=PokeIDCR_b_TCPCommTerminated
      FsftIDCR_I_ACOutCurrent1: client-com-spec=FsftIDCR_I_ACOutCurrent1, required-interface=FsftIDCR_I_ACOutCurrent1
      PokeIDCR_I_ACOutCurrent1: client-com-spec=PokeIDCR_I_ACOutCurrent1, required-interface=PokeIDCR_I_ACOutCurrent1
      FsftIDCR_I_ACOutCurrent2: client-com-spec=FsftIDCR_I_ACOutCurrent2, required-interface=FsftIDCR_I_ACOutCurrent2
      PokeIDCR_I_ACOutCurrent2: client-com-spec=PokeIDCR_I_ACOutCurrent2, required-interface=PokeIDCR_I_ACOutCurrent2
      FsftIDCR_I_ACOutCurrent3: client-com-spec=FsftIDCR_I_ACOutCurrent3, required-interface=FsftIDCR_I_ACOutCurrent3
      PokeIDCR_I_ACOutCurrent3: client-com-spec=PokeIDCR_I_ACOutCurrent3, required-interface=PokeIDCR_I_ACOutCurrent3
      FsftIDCR_U_ACOutVoltage1: client-com-spec=FsftIDCR_U_ACOutVoltage1, required-interface=FsftIDCR_U_ACOutVoltage1
      PokeIDCR_U_ACOutVoltage1: client-com-spec=PokeIDCR_U_ACOutVoltage1, required-interface=PokeIDCR_U_ACOutVoltage1
      FsftIDCR_U_ACOutVoltage2: client-com-spec=FsftIDCR_U_ACOutVoltage2, required-interface=FsftIDCR_U_ACOutVoltage2
      PokeIDCR_U_ACOutVoltage2: client-com-spec=PokeIDCR_U_ACOutVoltage2, required-interface=PokeIDCR_U_ACOutVoltage2
      FsftIDCR_U_ACOutVoltage3: client-com-spec=FsftIDCR_U_ACOutVoltage3, required-interface=FsftIDCR_U_ACOutVoltage3
      PokeIDCR_U_ACOutVoltage3: client-com-spec=PokeIDCR_U_ACOutVoltage3, required-interface=PokeIDCR_U_ACOutVoltage3
      FsftIDCR_f_ACOutFreq: client-com-spec=FsftIDCR_f_ACOutFreq, required-interface=FsftIDCR_f_ACOutFreq
      PokeIDCR_f_ACOutFreq: client-com-spec=PokeIDCR_f_ACOutFreq, required-interface=PokeIDCR_f_ACOutFreq
      FsftIDCR_I_DCInCurrent: client-com-spec=FsftIDCR_I_DCInCurrent, required-interface=FsftIDCR_I_DCInCurrent
      PokeIDCR_I_DCInCurrent: client-com-spec=PokeIDCR_I_DCInCurrent, required-interface=PokeIDCR_I_DCInCurrent
      FsftIDCR_U_DCInVoltage: client-com-spec=FsftIDCR_U_DCInVoltage, required-interface=FsftIDCR_U_DCInVoltage
      PokeIDCR_U_DCInVoltage: client-com-spec=PokeIDCR_U_DCInVoltage, required-interface=PokeIDCR_U_DCInVoltage
      FsftIDCR_e_DschrgFaultSts: client-com-spec=FsftIDCR_e_DschrgFaultSts, required-interface=FsftIDCR_e_DschrgFaultSts
      PokeIDCR_e_DschrgFaultSts: client-com-spec=PokeIDCR_e_DschrgFaultSts, required-interface=PokeIDCR_e_DschrgFaultSts
      FsftIDCR_b_IDCM_GFCI_FaultSts: variation-point={short-label=vpFsftIDCR_b_IDCM_GFCI_FaultSts, sw-syscond=1}, client-com-spec=FsftIDCR_b_IDCM_GFCI_FaultSts, required-interface=FsftIDCR_b_IDCM_GFCI_FaultSts
      PokeIDCR_b_IDCM_GFCI_FaultSts: variation-point={short-label=vpPokeIDCR_b_IDCM_GFCI_FaultSts, sw-syscond=1}, client-com-spec=PokeIDCR_b_IDCM_GFCI_FaultSts, required-interface=PokeIDCR_b_IDCM_GFCI_FaultSts
      FsftIDCR_f_V2XFrequency: client-com-spec=FsftIDCR_f_V2XFrequency, required-interface=FsftIDCR_f_V2XFrequency
      PokeIDCR_f_V2XFrequency: client-com-spec=PokeIDCR_f_V2XFrequency, required-interface=PokeIDCR_f_V2XFrequency
      FsftIDCR_b_V2XSts: client-com-spec=FsftIDCR_b_V2XSts, required-interface=FsftIDCR_b_V2XSts
      PokeIDCR_b_V2XSts: client-com-spec=PokeIDCR_b_V2XSts, required-interface=PokeIDCR_b_V2XSts
      FsftIDCR_I_AcOutCurrent: client-com-spec=FsftIDCR_I_AcOutCurrent, required-interface=FsftIDCR_I_AcOutCurrent
      PokeIDCR_I_AcOutCurrent: client-com-spec=PokeIDCR_I_AcOutCurrent, required-interface=PokeIDCR_I_AcOutCurrent
      FsftIDCR_f_AcOutFrequency: client-com-spec=FsftIDCR_f_AcOutFrequency, required-interface=FsftIDCR_f_AcOutFrequency
      PokeIDCR_f_AcOutFrequency: client-com-spec=PokeIDCR_f_AcOutFrequency, required-interface=PokeIDCR_f_AcOutFrequency
      FsftIDCR_U_AcOutVoltage: client-com-spec=FsftIDCR_U_AcOutVoltage, required-interface=FsftIDCR_U_AcOutVoltage
      PokeIDCR_U_AcOutVoltage: client-com-spec=PokeIDCR_U_AcOutVoltage, required-interface=PokeIDCR_U_AcOutVoltage
      FsftIDCR_P_AvailablePower: client-com-spec=FsftIDCR_P_AvailablePower, required-interface=FsftIDCR_P_AvailablePower
      PokeIDCR_P_AvailablePower: client-com-spec=PokeIDCR_P_AvailablePower, required-interface=PokeIDCR_P_AvailablePower
      FsftIDCR_e_V2XDerateRsn: client-com-spec=FsftIDCR_e_V2XDerateRsn, required-interface=FsftIDCR_e_V2XDerateRsn
      PokeIDCR_e_V2XDerateRsn: client-com-spec=PokeIDCR_e_V2XDerateRsn, required-interface=PokeIDCR_e_V2XDerateRsn
      FsftIDCR_b_V2XDerateSts: client-com-spec=FsftIDCR_b_V2XDerateSts, required-interface=FsftIDCR_b_V2XDerateSts
      PokeIDCR_b_V2XDerateSts: client-com-spec=PokeIDCR_b_V2XDerateSts, required-interface=PokeIDCR_b_V2XDerateSts
      FsftIDCR_b_V2XFailSts: client-com-spec=FsftIDCR_b_V2XFailSts, required-interface=FsftIDCR_b_V2XFailSts
      PokeIDCR_b_V2XFailSts: client-com-spec=PokeIDCR_b_V2XFailSts, required-interface=PokeIDCR_b_V2XFailSts
      FsftIDCR_e_V2XFaultRsn: client-com-spec=FsftIDCR_e_V2XFaultRsn, required-interface=FsftIDCR_e_V2XFaultRsn
      PokeIDCR_e_V2XFaultRsn: client-com-spec=PokeIDCR_e_V2XFaultRsn, required-interface=PokeIDCR_e_V2XFaultRsn
      FsftIDCR_I_V2XInCurrent: client-com-spec=FsftIDCR_I_V2XInCurrent, required-interface=FsftIDCR_I_V2XInCurrent
      PokeIDCR_I_V2XInCurrent: client-com-spec=PokeIDCR_I_V2XInCurrent, required-interface=PokeIDCR_I_V2XInCurrent
      FsftIDCR_U_V2XInVoltage: client-com-spec=FsftIDCR_U_V2XInVoltage, required-interface=FsftIDCR_U_V2XInVoltage
      PokeIDCR_U_V2XInVoltage: client-com-spec=PokeIDCR_U_V2XInVoltage, required-interface=PokeIDCR_U_V2XInVoltage
      FsftIDCR_e_V2XInterlockSts: client-com-spec=FsftIDCR_e_V2XInterlockSts, required-interface=FsftIDCR_e_V2XInterlockSts
      PokeIDCR_e_V2XInterlockSts: client-com-spec=PokeIDCR_e_V2XInterlockSts, required-interface=PokeIDCR_e_V2XInterlockSts
      FsftIDCR_U_V2XLVFeed: client-com-spec=FsftIDCR_U_V2XLVFeed, required-interface=FsftIDCR_U_V2XLVFeed
      PokeIDCR_U_V2XLVFeed: client-com-spec=PokeIDCR_U_V2XLVFeed, required-interface=PokeIDCR_U_V2XLVFeed
      FsftIDCR_e_V2XModeFeedback: client-com-spec=FsftIDCR_e_V2XModeFeedback, required-interface=FsftIDCR_e_V2XModeFeedback
      PokeIDCR_e_V2XModeFeedback: client-com-spec=PokeIDCR_e_V2XModeFeedback, required-interface=PokeIDCR_e_V2XModeFeedback
